VERSION "0.0.1"

NS_ :

BS_:

BU_: orin front_left_wheel back_left_wheel back_right_wheel front_right_wheel front_left_pivot back_left_pivot back_right_pivot front_right_pivot

BO_ 16 flw_all_stop: 0 orin

BO_ 17 flw_twitch_forward: 0 orin

BO_ 18 flw_twitch_backward: 0 orin

BO_ 19 flw_drive_at_speed: 2 orin
 SG_ velocity : 7|16@0- (1,0) [0|0] ""  front_left_wheel

BO_ 20 flw_drive_to_position: 2 orin
 SG_ position : 7|16@0- (1,0) [0|0] ""  front_left_wheel

BO_ 21 flw_drive_at_current: 2 orin
 SG_ effort : 7|16@0- (1,0) [0|0] ""  front_left_wheel

BO_ 22 flw_drive_open_loop: 4 orin
 SG_ open_loop_velocity : 23|16@0- (1,0) [0|0] ""  front_left_wheel
 SG_ open_loop_current : 7|16@0- (1,0) [0|0] ""  front_left_wheel

BO_ 23 flw_home_rotor: 0 orin

BO_ 24 flw_zero_resolver: 0 orin

BO_ 25 flw_get_configuration: 1 orin
 SG_ configuration : 7|8@0- (1,0) [0|0] ""  front_left_wheel

BO_ 26 flw_set_configuration: 4 orin
 SG_ shift_amount_0000_0001_0002_0004 m9 : 31|8@0+ (1,0) [0|0] "" Vector__XXX
 SG_ shift_amount_0000_0001_0002_0004 m8 : 31|8@0+ (1,0) [0|0] "" Vector__XXX
 SG_ shift_amount_0000_0001_0002_0004 m5 : 31|8@0+ (1,0) [0|0] "" Vector__XXX
 SG_ shift_amount_0000_0001_0002_0004 m4 : 31|8@0+ (1,0) [0|0] "" Vector__XXX
 SG_ shift_amount_0000_0001_0002_0004 m2 : 31|8@0+ (1,0) [0|0] "" Vector__XXX
 SG_ shift_amount_0000_0001_0002_0004 m1 : 31|8@0+ (1,0) [0|0] "" Vector__XXX
 SG_ speed_0000_0001_0002 m14 : 15|8@0+ (1,0) [0|0] "" Vector__XXX
 SG_ speed_0000_0001_0002 m13 : 15|8@0+ (1,0) [0|0] "" Vector__XXX
 SG_ speed_0000_0001_0002 m12 : 15|8@0+ (1,0) [0|0] "" Vector__XXX
 SG_ speed_0000_0001_0002 m11 : 15|8@0+ (1,0) [0|0] "" Vector__XXX
 SG_ max_position m10 : 15|16@0+ (1,0) [0|0] "" Vector__XXX
 SG_ fractional_0000_0001_0002_0_0004 m9 : 15|16@0+ (1,0) [0|0] "" Vector__XXX
 SG_ fractional_0000_0001_0002_0_0004 m8 : 15|16@0+ (1,0) [0|0] "" Vector__XXX
 SG_ min_interval m7 : 15|16@0+ (1,0) [0|0] "" Vector__XXX
 SG_ max_velocity m6 : 15|16@0+ (1,0) [0|0] "" Vector__XXX
 SG_ fractional_0000_0001_0002_0_0004 m5 : 15|16@0+ (1,0) [0|0] "" Vector__XXX
 SG_ fractional_0000_0001_0002_0_0004 m4 : 15|16@0+ (1,0) [0|0] "" Vector__XXX
 SG_ max_current m3 : 15|16@0+ (1,0) [0|0] "" Vector__XXX
 SG_ fractional_0000_0001_0002_0_0004 m2 : 15|16@0+ (1,0) [0|0] "" Vector__XXX
 SG_ fractional_0000_0001_0002_0_0004 m1 : 15|16@0+ (1,0) [0|0] "" Vector__XXX
 SG_ value m0 : 15|8@0+ (1,0) [0|0] "" Vector__XXX
 SG_ configuration M : 7|8@0+ (1,0) [0|0] ""  front_left_wheel

BO_ 27 flw_reset_blcmd: 0 orin

BO_ 28 flw_reset_resolver: 0 orin

BO_ 29 flw_read_gate_driver_fault: 0 orin

BO_ 1041 flw_telemetry_packet_1: 4 front_left_wheel
 SG_ q_current : 23|16@0- (1,0) [0|0] ""  orin
 SG_ velocity : 7|16@0- (1,0) [0|0] ""  orin

BO_ 1042 flw_telemetry_packet_2: 4 front_left_wheel
 SG_ d_current : 23|16@0- (1,0) [0|0] ""  orin
 SG_ interval : 7|16@0- (1,0) [0|0] ""  orin

BO_ 1043 flw_telemetry_packet_3: 4 front_left_wheel
 SG_ resolver_velocity : 23|16@0- (1,0) [0|0] ""  orin
 SG_ resolver_position : 7|16@0- (1,0) [0|0] ""  orin

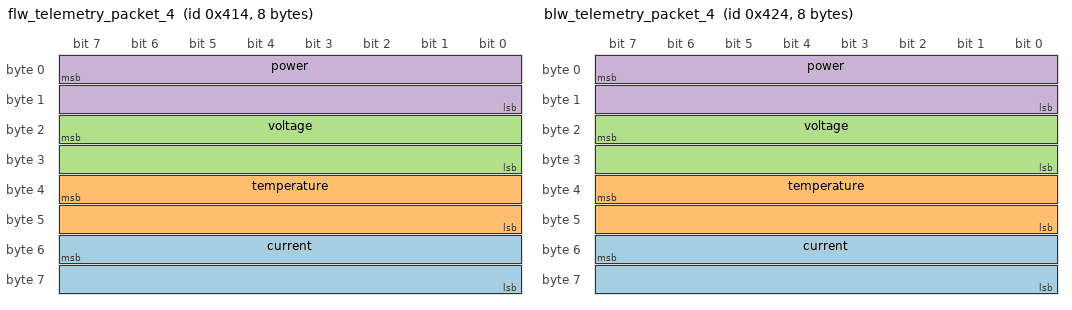
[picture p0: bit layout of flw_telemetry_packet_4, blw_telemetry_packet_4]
BO_ 1044 flw_telemetry_packet_4: 8 front_left_wheel
 SG_ current : 55|16@0- (1,0) [0|0] ""  orin
 SG_ temperature : 39|16@0- (1,0) [0|0] ""  orin
 SG_ voltage : 23|16@0- (1,0) [0|0] ""  orin
 SG_ power : 7|16@0- (1,0) [0|0] ""  orin

BO_ 1040 flw_log: 2 front_left_wheel
 SG_ gate_driver_condition m3 : 15|8@0+ (1,0) [0|0] "" Vector__XXX
 SG_ info_message m2 : 15|8@0- (1,0) [0|0] "" Vector__XXX
 SG_ warning_message m1 : 15|8@0- (1,0) [0|0] "" Vector__XXX
 SG_ error_message m0 : 15|8@0- (1,0) [0|0] "" Vector__XXX
 SG_ log_message M : 7|8@0- (1,0) [0|0] ""  orin

BO_ 1049 flw_current_configuration: 4 front_left_wheel
 SG_ shift_amount_0000_0001_0002_0004 m9 : 31|8@0+ (1,0) [0|0] "" Vector__XXX
 SG_ shift_amount_0000_0001_0002_0004 m8 : 31|8@0+ (1,0) [0|0] "" Vector__XXX
 SG_ shift_amount_0000_0001_0002_0004 m5 : 31|8@0+ (1,0) [0|0] "" Vector__XXX
 SG_ shift_amount_0000_0001_0002_0004 m4 : 31|8@0+ (1,0) [0|0] "" Vector__XXX
 SG_ shift_amount_0000_0001_0002_0004 m2 : 31|8@0+ (1,0) [0|0] "" Vector__XXX
 SG_ shift_amount_0000_0001_0002_0004 m1 : 31|8@0+ (1,0) [0|0] "" Vector__XXX
 SG_ speed_0000_0001_0002 m14 : 15|8@0+ (1,0) [0|0] "" Vector__XXX
 SG_ speed_0000_0001_0002 m13 : 15|8@0+ (1,0) [0|0] "" Vector__XXX
 SG_ speed_0000_0001_0002 m12 : 15|8@0+ (1,0) [0|0] "" Vector__XXX
 SG_ speed_0000_0001_0002 m11 : 15|8@0+ (1,0) [0|0] "" Vector__XXX
 SG_ max_position m10 : 15|16@0+ (1,0) [0|0] "" Vector__XXX
 SG_ fractional_0000_0001_0002_0_0004 m9 : 15|16@0+ (1,0) [0|0] "" Vector__XXX
 SG_ fractional_0000_0001_0002_0_0004 m8 : 15|16@0+ (1,0) [0|0] "" Vector__XXX
 SG_ min_interval m7 : 15|16@0+ (1,0) [0|0] "" Vector__XXX
 SG_ max_velocity m6 : 15|16@0+ (1,0) [0|0] "" Vector__XXX
 SG_ fractional_0000_0001_0002_0_0004 m5 : 15|16@0+ (1,0) [0|0] "" Vector__XXX
 SG_ fractional_0000_0001_0002_0_0004 m4 : 15|16@0+ (1,0) [0|0] "" Vector__XXX
 SG_ max_current m3 : 15|16@0+ (1,0) [0|0] "" Vector__XXX
 SG_ fractional_0000_0001_0002_0_0004 m2 : 15|16@0+ (1,0) [0|0] "" Vector__XXX
 SG_ fractional_0000_0001_0002_0_0004 m1 : 15|16@0+ (1,0) [0|0] "" Vector__XXX
 SG_ value m0 : 15|8@0+ (1,0) [0|0] "" Vector__XXX
 SG_ configuration M : 7|8@0+ (1,0) [0|0] ""  orin

BO_ 32 blw_all_stop: 0 orin

BO_ 33 blw_twitch_forward: 0 orin

BO_ 34 blw_twitch_backward: 0 orin

BO_ 35 blw_drive_at_speed: 2 orin
 SG_ velocity : 7|16@0- (1,0) [0|0] ""  back_left_wheel

BO_ 36 blw_drive_to_position: 2 orin
 SG_ position : 7|16@0- (1,0) [0|0] ""  back_left_wheel

BO_ 37 blw_drive_at_current: 2 orin
 SG_ effort : 7|16@0- (1,0) [0|0] ""  back_left_wheel

BO_ 38 blw_drive_open_loop: 4 orin
 SG_ open_loop_velocity : 23|16@0- (1,0) [0|0] ""  back_left_wheel
 SG_ open_loop_current : 7|16@0- (1,0) [0|0] ""  back_left_wheel

BO_ 39 blw_home_rotor: 0 orin

BO_ 40 blw_zero_resolver: 0 orin

BO_ 41 blw_get_configuration: 1 orin
 SG_ configuration : 7|8@0- (1,0) [0|0] ""  back_left_wheel

BO_ 42 blw_set_configuration: 4 orin
 SG_ shift_amount_0000_0001_0002_0004 m9 : 31|8@0+ (1,0) [0|0] "" Vector__XXX
 SG_ shift_amount_0000_0001_0002_0004 m8 : 31|8@0+ (1,0) [0|0] "" Vector__XXX
 SG_ shift_amount_0000_0001_0002_0004 m5 : 31|8@0+ (1,0) [0|0] "" Vector__XXX
 SG_ shift_amount_0000_0001_0002_0004 m4 : 31|8@0+ (1,0) [0|0] "" Vector__XXX
 SG_ shift_amount_0000_0001_0002_0004 m2 : 31|8@0+ (1,0) [0|0] "" Vector__XXX
 SG_ shift_amount_0000_0001_0002_0004 m1 : 31|8@0+ (1,0) [0|0] "" Vector__XXX
 SG_ speed_0000_0001_0002 m14 : 15|8@0+ (1,0) [0|0] "" Vector__XXX
 SG_ speed_0000_0001_0002 m13 : 15|8@0+ (1,0) [0|0] "" Vector__XXX
 SG_ speed_0000_0001_0002 m12 : 15|8@0+ (1,0) [0|0] "" Vector__XXX
 SG_ speed_0000_0001_0002 m11 : 15|8@0+ (1,0) [0|0] "" Vector__XXX
 SG_ max_position m10 : 15|16@0+ (1,0) [0|0] "" Vector__XXX
 SG_ fractional_0000_0001_0002_0_0004 m9 : 15|16@0+ (1,0) [0|0] "" Vector__XXX
 SG_ fractional_0000_0001_0002_0_0004 m8 : 15|16@0+ (1,0) [0|0] "" Vector__XXX
 SG_ min_interval m7 : 15|16@0+ (1,0) [0|0] "" Vector__XXX
 SG_ max_velocity m6 : 15|16@0+ (1,0) [0|0] "" Vector__XXX
 SG_ fractional_0000_0001_0002_0_0004 m5 : 15|16@0+ (1,0) [0|0] "" Vector__XXX
 SG_ fractional_0000_0001_0002_0_0004 m4 : 15|16@0+ (1,0) [0|0] "" Vector__XXX
 SG_ max_current m3 : 15|16@0+ (1,0) [0|0] "" Vector__XXX
 SG_ fractional_0000_0001_0002_0_0004 m2 : 15|16@0+ (1,0) [0|0] "" Vector__XXX
 SG_ fractional_0000_0001_0002_0_0004 m1 : 15|16@0+ (1,0) [0|0] "" Vector__XXX
 SG_ value m0 : 15|8@0+ (1,0) [0|0] "" Vector__XXX
 SG_ configuration M : 7|8@0+ (1,0) [0|0] ""  back_left_wheel

BO_ 43 blw_reset_blcmd: 0 orin

BO_ 44 blw_reset_resolver: 0 orin

BO_ 45 blw_read_gate_driver_fault: 0 orin

BO_ 1057 blw_telemetry_packet_1: 4 back_left_wheel
 SG_ q_current : 23|16@0- (1,0) [0|0] ""  orin
 SG_ velocity : 7|16@0- (1,0) [0|0] ""  orin

BO_ 1058 blw_telemetry_packet_2: 4 back_left_wheel
 SG_ d_current : 23|16@0- (1,0) [0|0] ""  orin
 SG_ interval : 7|16@0- (1,0) [0|0] ""  orin

BO_ 1059 blw_telemetry_packet_3: 4 back_left_wheel
 SG_ resolver_velocity : 23|16@0- (1,0) [0|0] ""  orin
 SG_ resolver_position : 7|16@0- (1,0) [0|0] ""  orin

BO_ 1060 blw_telemetry_packet_4: 8 back_left_wheel
 SG_ current : 55|16@0- (1,0) [0|0] ""  orin
 SG_ temperature : 39|16@0- (1,0) [0|0] ""  orin
 SG_ voltage : 23|16@0- (1,0) [0|0] ""  orin
 SG_ power : 7|16@0- (1,0) [0|0] ""  orin

BO_ 1056 blw_log: 2 back_left_wheel
 SG_ gate_driver_condition m3 : 15|8@0+ (1,0) [0|0] "" Vector__XXX
 SG_ info_message m2 : 15|8@0- (1,0) [0|0] "" Vector__XXX
 SG_ warning_message m1 : 15|8@0- (1,0) [0|0] "" Vector__XXX
 SG_ error_message m0 : 15|8@0- (1,0) [0|0] "" Vector__XXX
 SG_ log_message M : 7|8@0- (1,0) [0|0] ""  orin

BO_ 1065 blw_current_configuration: 4 back_left_wheel
 SG_ shift_amount_0000_0001_0002_0004 m9 : 31|8@0+ (1,0) [0|0] "" Vector__XXX
 SG_ shift_amount_0000_0001_0002_0004 m8 : 31|8@0+ (1,0) [0|0] "" Vector__XXX
 SG_ shift_amount_0000_0001_0002_0004 m5 : 31|8@0+ (1,0) [0|0] "" Vector__XXX
 SG_ shift_amount_0000_0001_0002_0004 m4 : 31|8@0+ (1,0) [0|0] "" Vector__XXX
 SG_ shift_amount_0000_0001_0002_0004 m2 : 31|8@0+ (1,0) [0|0] "" Vector__XXX
 SG_ shift_amount_0000_0001_0002_0004 m1 : 31|8@0+ (1,0) [0|0] "" Vector__XXX
 SG_ speed_0000_0001_0002 m14 : 15|8@0+ (1,0) [0|0] "" Vector__XXX
 SG_ speed_0000_0001_0002 m13 : 15|8@0+ (1,0) [0|0] "" Vector__XXX
 SG_ speed_0000_0001_0002 m12 : 15|8@0+ (1,0) [0|0] "" Vector__XXX
 SG_ speed_0000_0001_0002 m11 : 15|8@0+ (1,0) [0|0] "" Vector__XXX
 SG_ max_position m10 : 15|16@0+ (1,0) [0|0] "" Vector__XXX
 SG_ fractional_0000_0001_0002_0_0004 m9 : 15|16@0+ (1,0) [0|0] "" Vector__XXX
 SG_ fractional_0000_0001_0002_0_0004 m8 : 15|16@0+ (1,0) [0|0] "" Vector__XXX
 SG_ min_interval m7 : 15|16@0+ (1,0) [0|0] "" Vector__XXX
 SG_ max_velocity m6 : 15|16@0+ (1,0) [0|0] "" Vector__XXX
 SG_ fractional_0000_0001_0002_0_0004 m5 : 15|16@0+ (1,0) [0|0] "" Vector__XXX
 SG_ fractional_0000_0001_0002_0_0004 m4 : 15|16@0+ (1,0) [0|0] "" Vector__XXX
 SG_ max_current m3 : 15|16@0+ (1,0) [0|0] "" Vector__XXX
 SG_ fractional_0000_0001_0002_0_0004 m2 : 15|16@0+ (1,0) [0|0] "" Vector__XXX
 SG_ fractional_0000_0001_0002_0_0004 m1 : 15|16@0+ (1,0) [0|0] "" Vector__XXX
 SG_ value m0 : 15|8@0+ (1,0) [0|0] "" Vector__XXX
 SG_ configuration M : 7|8@0+ (1,0) [0|0] ""  orin

BO_ 48 brw_all_stop: 0 orin

BO_ 49 brw_twitch_forward: 0 orin

BO_ 50 brw_twitch_backward: 0 orin

BO_ 51 brw_drive_at_speed: 2 orin
 SG_ velocity : 7|16@0- (1,0) [0|0] ""  back_right_wheel

BO_ 52 brw_drive_to_position: 2 orin
 SG_ position : 7|16@0- (1,0) [0|0] ""  back_right_wheel

BO_ 53 brw_drive_at_current: 2 orin
 SG_ effort : 7|16@0- (1,0) [0|0] ""  back_right_wheel

BO_ 54 brw_drive_open_loop: 4 orin
 SG_ open_loop_velocity : 23|16@0- (1,0) [0|0] ""  back_right_wheel
 SG_ open_loop_current : 7|16@0- (1,0) [0|0] ""  back_right_wheel

BO_ 55 brw_home_rotor: 0 orin

BO_ 56 brw_zero_resolver: 0 orin

BO_ 57 brw_get_configuration: 1 orin
 SG_ configuration : 7|8@0- (1,0) [0|0] ""  back_right_wheel

BO_ 58 brw_set_configuration: 4 orin
 SG_ shift_amount_0000_0001_0002_0004 m9 : 31|8@0+ (1,0) [0|0] "" Vector__XXX
 SG_ shift_amount_0000_0001_0002_0004 m8 : 31|8@0+ (1,0) [0|0] "" Vector__XXX
 SG_ shift_amount_0000_0001_0002_0004 m5 : 31|8@0+ (1,0) [0|0] "" Vector__XXX
 SG_ shift_amount_0000_0001_0002_0004 m4 : 31|8@0+ (1,0) [0|0] "" Vector__XXX
 SG_ shift_amount_0000_0001_0002_0004 m2 : 31|8@0+ (1,0) [0|0] "" Vector__XXX
 SG_ shift_amount_0000_0001_0002_0004 m1 : 31|8@0+ (1,0) [0|0] "" Vector__XXX
 SG_ speed_0000_0001_0002 m14 : 15|8@0+ (1,0) [0|0] "" Vector__XXX
 SG_ speed_0000_0001_0002 m13 : 15|8@0+ (1,0) [0|0] "" Vector__XXX
 SG_ speed_0000_0001_0002 m12 : 15|8@0+ (1,0) [0|0] "" Vector__XXX
 SG_ speed_0000_0001_0002 m11 : 15|8@0+ (1,0) [0|0] "" Vector__XXX
 SG_ max_position m10 : 15|16@0+ (1,0) [0|0] "" Vector__XXX
 SG_ fractional_0000_0001_0002_0_0004 m9 : 15|16@0+ (1,0) [0|0] "" Vector__XXX
 SG_ fractional_0000_0001_0002_0_0004 m8 : 15|16@0+ (1,0) [0|0] "" Vector__XXX
 SG_ min_interval m7 : 15|16@0+ (1,0) [0|0] "" Vector__XXX
 SG_ max_velocity m6 : 15|16@0+ (1,0) [0|0] "" Vector__XXX
 SG_ fractional_0000_0001_0002_0_0004 m5 : 15|16@0+ (1,0) [0|0] "" Vector__XXX
 SG_ fractional_0000_0001_0002_0_0004 m4 : 15|16@0+ (1,0) [0|0] "" Vector__XXX
 SG_ max_current m3 : 15|16@0+ (1,0) [0|0] "" Vector__XXX
 SG_ fractional_0000_0001_0002_0_0004 m2 : 15|16@0+ (1,0) [0|0] "" Vector__XXX
 SG_ fractional_0000_0001_0002_0_0004 m1 : 15|16@0+ (1,0) [0|0] "" Vector__XXX
 SG_ value m0 : 15|8@0+ (1,0) [0|0] "" Vector__XXX
 SG_ configuration M : 7|8@0+ (1,0) [0|0] ""  back_right_wheel

BO_ 59 brw_reset_blcmd: 0 orin

BO_ 60 brw_reset_resolver: 0 orin

BO_ 61 brw_read_gate_driver_fault: 0 orin

BO_ 1073 brw_telemetry_packet_1: 4 back_right_wheel
 SG_ q_current : 23|16@0- (1,0) [0|0] ""  orin
 SG_ velocity : 7|16@0- (1,0) [0|0] ""  orin

BO_ 1074 brw_telemetry_packet_2: 4 back_right_wheel
 SG_ d_current : 23|16@0- (1,0) [0|0] ""  orin
 SG_ interval : 7|16@0- (1,0) [0|0] ""  orin

BO_ 1075 brw_telemetry_packet_3: 4 back_right_wheel
 SG_ resolver_velocity : 23|16@0- (1,0) [0|0] ""  orin
 SG_ resolver_position : 7|16@0- (1,0) [0|0] ""  orin

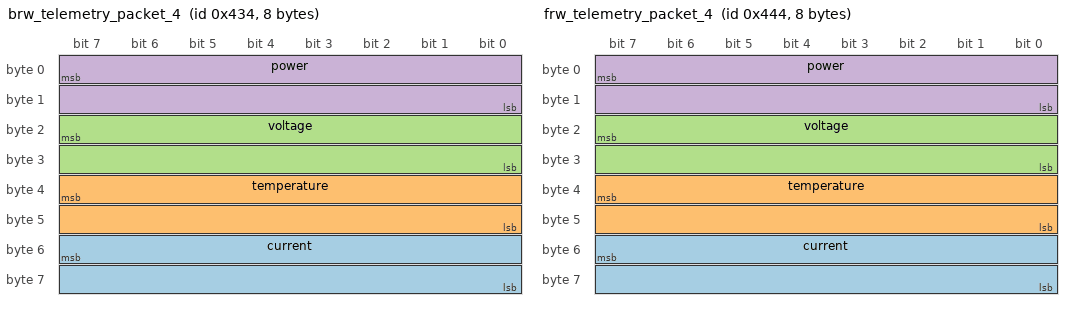
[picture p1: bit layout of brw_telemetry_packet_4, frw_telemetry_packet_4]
BO_ 1076 brw_telemetry_packet_4: 8 back_right_wheel
 SG_ current : 55|16@0- (1,0) [0|0] ""  orin
 SG_ temperature : 39|16@0- (1,0) [0|0] ""  orin
 SG_ voltage : 23|16@0- (1,0) [0|0] ""  orin
 SG_ power : 7|16@0- (1,0) [0|0] ""  orin

BO_ 1072 brw_log: 2 back_right_wheel
 SG_ gate_driver_condition m3 : 15|8@0+ (1,0) [0|0] "" Vector__XXX
 SG_ info_message m2 : 15|8@0- (1,0) [0|0] "" Vector__XXX
 SG_ warning_message m1 : 15|8@0- (1,0) [0|0] "" Vector__XXX
 SG_ error_message m0 : 15|8@0- (1,0) [0|0] "" Vector__XXX
 SG_ log_message M : 7|8@0- (1,0) [0|0] ""  orin

BO_ 1081 brw_current_configuration: 4 back_right_wheel
 SG_ shift_amount_0000_0001_0002_0004 m9 : 31|8@0+ (1,0) [0|0] "" Vector__XXX
 SG_ shift_amount_0000_0001_0002_0004 m8 : 31|8@0+ (1,0) [0|0] "" Vector__XXX
 SG_ shift_amount_0000_0001_0002_0004 m5 : 31|8@0+ (1,0) [0|0] "" Vector__XXX
 SG_ shift_amount_0000_0001_0002_0004 m4 : 31|8@0+ (1,0) [0|0] "" Vector__XXX
 SG_ shift_amount_0000_0001_0002_0004 m2 : 31|8@0+ (1,0) [0|0] "" Vector__XXX
 SG_ shift_amount_0000_0001_0002_0004 m1 : 31|8@0+ (1,0) [0|0] "" Vector__XXX
 SG_ speed_0000_0001_0002 m14 : 15|8@0+ (1,0) [0|0] "" Vector__XXX
 SG_ speed_0000_0001_0002 m13 : 15|8@0+ (1,0) [0|0] "" Vector__XXX
 SG_ speed_0000_0001_0002 m12 : 15|8@0+ (1,0) [0|0] "" Vector__XXX
 SG_ speed_0000_0001_0002 m11 : 15|8@0+ (1,0) [0|0] "" Vector__XXX
 SG_ max_position m10 : 15|16@0+ (1,0) [0|0] "" Vector__XXX
 SG_ fractional_0000_0001_0002_0_0004 m9 : 15|16@0+ (1,0) [0|0] "" Vector__XXX
 SG_ fractional_0000_0001_0002_0_0004 m8 : 15|16@0+ (1,0) [0|0] "" Vector__XXX
 SG_ min_interval m7 : 15|16@0+ (1,0) [0|0] "" Vector__XXX
 SG_ max_velocity m6 : 15|16@0+ (1,0) [0|0] "" Vector__XXX
 SG_ fractional_0000_0001_0002_0_0004 m5 : 15|16@0+ (1,0) [0|0] "" Vector__XXX
 SG_ fractional_0000_0001_0002_0_0004 m4 : 15|16@0+ (1,0) [0|0] "" Vector__XXX
 SG_ max_current m3 : 15|16@0+ (1,0) [0|0] "" Vector__XXX
 SG_ fractional_0000_0001_0002_0_0004 m2 : 15|16@0+ (1,0) [0|0] "" Vector__XXX
 SG_ fractional_0000_0001_0002_0_0004 m1 : 15|16@0+ (1,0) [0|0] "" Vector__XXX
 SG_ value m0 : 15|8@0+ (1,0) [0|0] "" Vector__XXX
 SG_ configuration M : 7|8@0+ (1,0) [0|0] ""  orin

BO_ 64 frw_all_stop: 0 orin

BO_ 65 frw_twitch_forward: 0 orin

BO_ 66 frw_twitch_backward: 0 orin

BO_ 67 frw_drive_at_speed: 2 orin
 SG_ velocity : 7|16@0- (1,0) [0|0] ""  front_right_wheel

BO_ 68 frw_drive_to_position: 2 orin
 SG_ position : 7|16@0- (1,0) [0|0] ""  front_right_wheel

BO_ 69 frw_drive_at_current: 2 orin
 SG_ effort : 7|16@0- (1,0) [0|0] ""  front_right_wheel

BO_ 70 frw_drive_open_loop: 4 orin
 SG_ open_loop_velocity : 23|16@0- (1,0) [0|0] ""  front_right_wheel
 SG_ open_loop_current : 7|16@0- (1,0) [0|0] ""  front_right_wheel

BO_ 71 frw_home_rotor: 0 orin

BO_ 72 frw_zero_resolver: 0 orin

BO_ 73 frw_get_configuration: 1 orin
 SG_ configuration : 7|8@0- (1,0) [0|0] ""  front_right_wheel

BO_ 74 frw_set_configuration: 4 orin
 SG_ shift_amount_0000_0001_0002_0004 m9 : 31|8@0+ (1,0) [0|0] "" Vector__XXX
 SG_ shift_amount_0000_0001_0002_0004 m8 : 31|8@0+ (1,0) [0|0] "" Vector__XXX
 SG_ shift_amount_0000_0001_0002_0004 m5 : 31|8@0+ (1,0) [0|0] "" Vector__XXX
 SG_ shift_amount_0000_0001_0002_0004 m4 : 31|8@0+ (1,0) [0|0] "" Vector__XXX
 SG_ shift_amount_0000_0001_0002_0004 m2 : 31|8@0+ (1,0) [0|0] "" Vector__XXX
 SG_ shift_amount_0000_0001_0002_0004 m1 : 31|8@0+ (1,0) [0|0] "" Vector__XXX
 SG_ speed_0000_0001_0002 m14 : 15|8@0+ (1,0) [0|0] "" Vector__XXX
 SG_ speed_0000_0001_0002 m13 : 15|8@0+ (1,0) [0|0] "" Vector__XXX
 SG_ speed_0000_0001_0002 m12 : 15|8@0+ (1,0) [0|0] "" Vector__XXX
 SG_ speed_0000_0001_0002 m11 : 15|8@0+ (1,0) [0|0] "" Vector__XXX
 SG_ max_position m10 : 15|16@0+ (1,0) [0|0] "" Vector__XXX
 SG_ fractional_0000_0001_0002_0_0004 m9 : 15|16@0+ (1,0) [0|0] "" Vector__XXX
 SG_ fractional_0000_0001_0002_0_0004 m8 : 15|16@0+ (1,0) [0|0] "" Vector__XXX
 SG_ min_interval m7 : 15|16@0+ (1,0) [0|0] "" Vector__XXX
 SG_ max_velocity m6 : 15|16@0+ (1,0) [0|0] "" Vector__XXX
 SG_ fractional_0000_0001_0002_0_0004 m5 : 15|16@0+ (1,0) [0|0] "" Vector__XXX
 SG_ fractional_0000_0001_0002_0_0004 m4 : 15|16@0+ (1,0) [0|0] "" Vector__XXX
 SG_ max_current m3 : 15|16@0+ (1,0) [0|0] "" Vector__XXX
 SG_ fractional_0000_0001_0002_0_0004 m2 : 15|16@0+ (1,0) [0|0] "" Vector__XXX
 SG_ fractional_0000_0001_0002_0_0004 m1 : 15|16@0+ (1,0) [0|0] "" Vector__XXX
 SG_ value m0 : 15|8@0+ (1,0) [0|0] "" Vector__XXX
 SG_ configuration M : 7|8@0+ (1,0) [0|0] ""  front_right_wheel

BO_ 75 frw_reset_blcmd: 0 orin

BO_ 76 frw_reset_resolver: 0 orin

BO_ 77 frw_read_gate_driver_fault: 0 orin

BO_ 1089 frw_telemetry_packet_1: 4 front_right_wheel
 SG_ q_current : 23|16@0- (1,0) [0|0] ""  orin
 SG_ velocity : 7|16@0- (1,0) [0|0] ""  orin

BO_ 1090 frw_telemetry_packet_2: 4 front_right_wheel
 SG_ d_current : 23|16@0- (1,0) [0|0] ""  orin
 SG_ interval : 7|16@0- (1,0) [0|0] ""  orin

BO_ 1091 frw_telemetry_packet_3: 4 front_right_wheel
 SG_ resolver_velocity : 23|16@0- (1,0) [0|0] ""  orin
 SG_ resolver_position : 7|16@0- (1,0) [0|0] ""  orin

BO_ 1092 frw_telemetry_packet_4: 8 front_right_wheel
 SG_ current : 55|16@0- (1,0) [0|0] ""  orin
 SG_ temperature : 39|16@0- (1,0) [0|0] ""  orin
 SG_ voltage : 23|16@0- (1,0) [0|0] ""  orin
 SG_ power : 7|16@0- (1,0) [0|0] ""  orin

BO_ 1088 frw_log: 2 front_right_wheel
 SG_ gate_driver_condition m3 : 15|8@0+ (1,0) [0|0] "" Vector__XXX
 SG_ info_message m2 : 15|8@0- (1,0) [0|0] "" Vector__XXX
 SG_ warning_message m1 : 15|8@0- (1,0) [0|0] "" Vector__XXX
 SG_ error_message m0 : 15|8@0- (1,0) [0|0] "" Vector__XXX
 SG_ log_message M : 7|8@0- (1,0) [0|0] ""  orin

BO_ 1097 frw_current_configuration: 4 front_right_wheel
 SG_ shift_amount_0000_0001_0002_0004 m9 : 31|8@0+ (1,0) [0|0] "" Vector__XXX
 SG_ shift_amount_0000_0001_0002_0004 m8 : 31|8@0+ (1,0) [0|0] "" Vector__XXX
 SG_ shift_amount_0000_0001_0002_0004 m5 : 31|8@0+ (1,0) [0|0] "" Vector__XXX
 SG_ shift_amount_0000_0001_0002_0004 m4 : 31|8@0+ (1,0) [0|0] "" Vector__XXX
 SG_ shift_amount_0000_0001_0002_0004 m2 : 31|8@0+ (1,0) [0|0] "" Vector__XXX
 SG_ shift_amount_0000_0001_0002_0004 m1 : 31|8@0+ (1,0) [0|0] "" Vector__XXX
 SG_ speed_0000_0001_0002 m14 : 15|8@0+ (1,0) [0|0] "" Vector__XXX
 SG_ speed_0000_0001_0002 m13 : 15|8@0+ (1,0) [0|0] "" Vector__XXX
 SG_ speed_0000_0001_0002 m12 : 15|8@0+ (1,0) [0|0] "" Vector__XXX
 SG_ speed_0000_0001_0002 m11 : 15|8@0+ (1,0) [0|0] "" Vector__XXX
 SG_ max_position m10 : 15|16@0+ (1,0) [0|0] "" Vector__XXX
 SG_ fractional_0000_0001_0002_0_0004 m9 : 15|16@0+ (1,0) [0|0] "" Vector__XXX
 SG_ fractional_0000_0001_0002_0_0004 m8 : 15|16@0+ (1,0) [0|0] "" Vector__XXX
 SG_ min_interval m7 : 15|16@0+ (1,0) [0|0] "" Vector__XXX
 SG_ max_velocity m6 : 15|16@0+ (1,0) [0|0] "" Vector__XXX
 SG_ fractional_0000_0001_0002_0_0004 m5 : 15|16@0+ (1,0) [0|0] "" Vector__XXX
 SG_ fractional_0000_0001_0002_0_0004 m4 : 15|16@0+ (1,0) [0|0] "" Vector__XXX
 SG_ max_current m3 : 15|16@0+ (1,0) [0|0] "" Vector__XXX
 SG_ fractional_0000_0001_0002_0_0004 m2 : 15|16@0+ (1,0) [0|0] "" Vector__XXX
 SG_ fractional_0000_0001_0002_0_0004 m1 : 15|16@0+ (1,0) [0|0] "" Vector__XXX
 SG_ value m0 : 15|8@0+ (1,0) [0|0] "" Vector__XXX
 SG_ configuration M : 7|8@0+ (1,0) [0|0] ""  orin

BO_ 80 flp_all_stop: 0 orin

BO_ 81 flp_twitch_forward: 0 orin

BO_ 82 flp_twitch_backward: 0 orin

BO_ 83 flp_drive_at_speed: 2 orin
 SG_ velocity : 7|16@0- (1,0) [0|0] ""  front_left_pivot

BO_ 84 flp_drive_to_position: 2 orin
 SG_ position : 7|16@0- (1,0) [0|0] ""  front_left_pivot

BO_ 85 flp_drive_at_current: 2 orin
 SG_ effort : 7|16@0- (1,0) [0|0] ""  front_left_pivot

BO_ 86 flp_drive_open_loop: 4 orin
 SG_ open_loop_velocity : 23|16@0- (1,0) [0|0] ""  front_left_pivot
 SG_ open_loop_current : 7|16@0- (1,0) [0|0] ""  front_left_pivot

BO_ 87 flp_home_rotor: 0 orin

BO_ 88 flp_zero_resolver: 0 orin

BO_ 89 flp_get_configuration: 1 orin
 SG_ configuration : 7|8@0- (1,0) [0|0] ""  front_left_pivot

BO_ 90 flp_set_configuration: 4 orin
 SG_ shift_amount_0000_0001_0002_0004 m9 : 31|8@0+ (1,0) [0|0] "" Vector__XXX
 SG_ shift_amount_0000_0001_0002_0004 m8 : 31|8@0+ (1,0) [0|0] "" Vector__XXX
 SG_ shift_amount_0000_0001_0002_0004 m5 : 31|8@0+ (1,0) [0|0] "" Vector__XXX
 SG_ shift_amount_0000_0001_0002_0004 m4 : 31|8@0+ (1,0) [0|0] "" Vector__XXX
 SG_ shift_amount_0000_0001_0002_0004 m2 : 31|8@0+ (1,0) [0|0] "" Vector__XXX
 SG_ shift_amount_0000_0001_0002_0004 m1 : 31|8@0+ (1,0) [0|0] "" Vector__XXX
 SG_ speed_0000_0001_0002 m14 : 15|8@0+ (1,0) [0|0] "" Vector__XXX
 SG_ speed_0000_0001_0002 m13 : 15|8@0+ (1,0) [0|0] "" Vector__XXX
 SG_ speed_0000_0001_0002 m12 : 15|8@0+ (1,0) [0|0] "" Vector__XXX
 SG_ speed_0000_0001_0002 m11 : 15|8@0+ (1,0) [0|0] "" Vector__XXX
 SG_ max_position m10 : 15|16@0+ (1,0) [0|0] "" Vector__XXX
 SG_ fractional_0000_0001_0002_0_0004 m9 : 15|16@0+ (1,0) [0|0] "" Vector__XXX
 SG_ fractional_0000_0001_0002_0_0004 m8 : 15|16@0+ (1,0) [0|0] "" Vector__XXX
 SG_ min_interval m7 : 15|16@0+ (1,0) [0|0] "" Vector__XXX
 SG_ max_velocity m6 : 15|16@0+ (1,0) [0|0] "" Vector__XXX
 SG_ fractional_0000_0001_0002_0_0004 m5 : 15|16@0+ (1,0) [0|0] "" Vector__XXX
 SG_ fractional_0000_0001_0002_0_0004 m4 : 15|16@0+ (1,0) [0|0] "" Vector__XXX
 SG_ max_current m3 : 15|16@0+ (1,0) [0|0] "" Vector__XXX
 SG_ fractional_0000_0001_0002_0_0004 m2 : 15|16@0+ (1,0) [0|0] "" Vector__XXX
 SG_ fractional_0000_0001_0002_0_0004 m1 : 15|16@0+ (1,0) [0|0] "" Vector__XXX
 SG_ value m0 : 15|8@0+ (1,0) [0|0] "" Vector__XXX
 SG_ configuration M : 7|8@0+ (1,0) [0|0] ""  front_left_pivot

BO_ 91 flp_reset_blcmd: 0 orin

BO_ 92 flp_reset_resolver: 0 orin

BO_ 93 flp_read_gate_driver_fault: 0 orin

BO_ 1105 flp_telemetry_packet_1: 4 front_left_pivot
 SG_ q_current : 23|16@0- (1,0) [0|0] ""  orin
 SG_ velocity : 7|16@0- (1,0) [0|0] ""  orin

BO_ 1106 flp_telemetry_packet_2: 4 front_left_pivot
 SG_ d_current : 23|16@0- (1,0) [0|0] ""  orin
 SG_ interval : 7|16@0- (1,0) [0|0] ""  orin

BO_ 1107 flp_telemetry_packet_3: 4 front_left_pivot
 SG_ resolver_velocity : 23|16@0- (1,0) [0|0] ""  orin
 SG_ resolver_position : 7|16@0- (1,0) [0|0] ""  orin

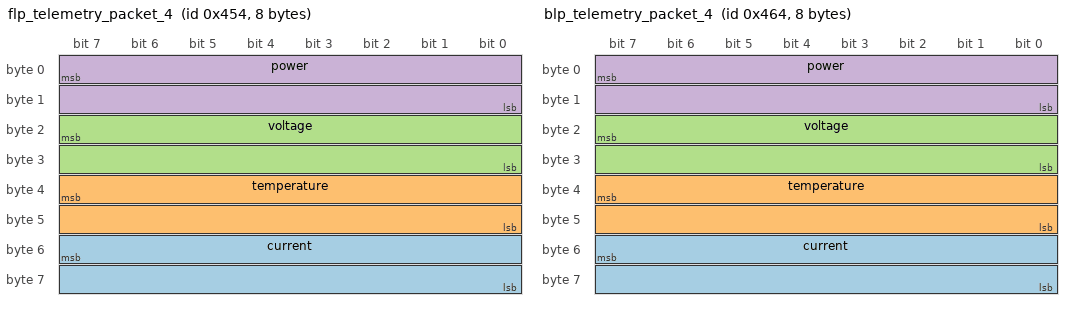
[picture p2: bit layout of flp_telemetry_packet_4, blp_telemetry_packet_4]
BO_ 1108 flp_telemetry_packet_4: 8 front_left_pivot
 SG_ current : 55|16@0- (1,0) [0|0] ""  orin
 SG_ temperature : 39|16@0- (1,0) [0|0] ""  orin
 SG_ voltage : 23|16@0- (1,0) [0|0] ""  orin
 SG_ power : 7|16@0- (1,0) [0|0] ""  orin

BO_ 1104 flp_log: 2 front_left_pivot
 SG_ gate_driver_condition m3 : 15|8@0+ (1,0) [0|0] "" Vector__XXX
 SG_ info_message m2 : 15|8@0- (1,0) [0|0] "" Vector__XXX
 SG_ warning_message m1 : 15|8@0- (1,0) [0|0] "" Vector__XXX
 SG_ error_message m0 : 15|8@0- (1,0) [0|0] "" Vector__XXX
 SG_ log_message M : 7|8@0- (1,0) [0|0] ""  orin

BO_ 1113 flp_current_configuration: 4 front_left_pivot
 SG_ shift_amount_0000_0001_0002_0004 m9 : 31|8@0+ (1,0) [0|0] "" Vector__XXX
 SG_ shift_amount_0000_0001_0002_0004 m8 : 31|8@0+ (1,0) [0|0] "" Vector__XXX
 SG_ shift_amount_0000_0001_0002_0004 m5 : 31|8@0+ (1,0) [0|0] "" Vector__XXX
 SG_ shift_amount_0000_0001_0002_0004 m4 : 31|8@0+ (1,0) [0|0] "" Vector__XXX
 SG_ shift_amount_0000_0001_0002_0004 m2 : 31|8@0+ (1,0) [0|0] "" Vector__XXX
 SG_ shift_amount_0000_0001_0002_0004 m1 : 31|8@0+ (1,0) [0|0] "" Vector__XXX
 SG_ speed_0000_0001_0002 m14 : 15|8@0+ (1,0) [0|0] "" Vector__XXX
 SG_ speed_0000_0001_0002 m13 : 15|8@0+ (1,0) [0|0] "" Vector__XXX
 SG_ speed_0000_0001_0002 m12 : 15|8@0+ (1,0) [0|0] "" Vector__XXX
 SG_ speed_0000_0001_0002 m11 : 15|8@0+ (1,0) [0|0] "" Vector__XXX
 SG_ max_position m10 : 15|16@0+ (1,0) [0|0] "" Vector__XXX
 SG_ fractional_0000_0001_0002_0_0004 m9 : 15|16@0+ (1,0) [0|0] "" Vector__XXX
 SG_ fractional_0000_0001_0002_0_0004 m8 : 15|16@0+ (1,0) [0|0] "" Vector__XXX
 SG_ min_interval m7 : 15|16@0+ (1,0) [0|0] "" Vector__XXX
 SG_ max_velocity m6 : 15|16@0+ (1,0) [0|0] "" Vector__XXX
 SG_ fractional_0000_0001_0002_0_0004 m5 : 15|16@0+ (1,0) [0|0] "" Vector__XXX
 SG_ fractional_0000_0001_0002_0_0004 m4 : 15|16@0+ (1,0) [0|0] "" Vector__XXX
 SG_ max_current m3 : 15|16@0+ (1,0) [0|0] "" Vector__XXX
 SG_ fractional_0000_0001_0002_0_0004 m2 : 15|16@0+ (1,0) [0|0] "" Vector__XXX
 SG_ fractional_0000_0001_0002_0_0004 m1 : 15|16@0+ (1,0) [0|0] "" Vector__XXX
 SG_ value m0 : 15|8@0+ (1,0) [0|0] "" Vector__XXX
 SG_ configuration M : 7|8@0+ (1,0) [0|0] ""  orin

BO_ 96 blp_all_stop: 0 orin

BO_ 97 blp_twitch_forward: 0 orin

BO_ 98 blp_twitch_backward: 0 orin

BO_ 99 blp_drive_at_speed: 2 orin
 SG_ velocity : 7|16@0- (1,0) [0|0] ""  back_left_pivot

BO_ 100 blp_drive_to_position: 2 orin
 SG_ position : 7|16@0- (1,0) [0|0] ""  back_left_pivot

BO_ 101 blp_drive_at_current: 2 orin
 SG_ effort : 7|16@0- (1,0) [0|0] ""  back_left_pivot

BO_ 102 blp_drive_open_loop: 4 orin
 SG_ open_loop_velocity : 23|16@0- (1,0) [0|0] ""  back_left_pivot
 SG_ open_loop_current : 7|16@0- (1,0) [0|0] ""  back_left_pivot

BO_ 103 blp_home_rotor: 0 orin

BO_ 104 blp_zero_resolver: 0 orin

BO_ 105 blp_get_configuration: 1 orin
 SG_ configuration : 7|8@0- (1,0) [0|0] ""  back_left_pivot

BO_ 106 blp_set_configuration: 4 orin
 SG_ shift_amount_0000_0001_0002_0004 m9 : 31|8@0+ (1,0) [0|0] "" Vector__XXX
 SG_ shift_amount_0000_0001_0002_0004 m8 : 31|8@0+ (1,0) [0|0] "" Vector__XXX
 SG_ shift_amount_0000_0001_0002_0004 m5 : 31|8@0+ (1,0) [0|0] "" Vector__XXX
 SG_ shift_amount_0000_0001_0002_0004 m4 : 31|8@0+ (1,0) [0|0] "" Vector__XXX
 SG_ shift_amount_0000_0001_0002_0004 m2 : 31|8@0+ (1,0) [0|0] "" Vector__XXX
 SG_ shift_amount_0000_0001_0002_0004 m1 : 31|8@0+ (1,0) [0|0] "" Vector__XXX
 SG_ speed_0000_0001_0002 m14 : 15|8@0+ (1,0) [0|0] "" Vector__XXX
 SG_ speed_0000_0001_0002 m13 : 15|8@0+ (1,0) [0|0] "" Vector__XXX
 SG_ speed_0000_0001_0002 m12 : 15|8@0+ (1,0) [0|0] "" Vector__XXX
 SG_ speed_0000_0001_0002 m11 : 15|8@0+ (1,0) [0|0] "" Vector__XXX
 SG_ max_position m10 : 15|16@0+ (1,0) [0|0] "" Vector__XXX
 SG_ fractional_0000_0001_0002_0_0004 m9 : 15|16@0+ (1,0) [0|0] "" Vector__XXX
 SG_ fractional_0000_0001_0002_0_0004 m8 : 15|16@0+ (1,0) [0|0] "" Vector__XXX
 SG_ min_interval m7 : 15|16@0+ (1,0) [0|0] "" Vector__XXX
 SG_ max_velocity m6 : 15|16@0+ (1,0) [0|0] "" Vector__XXX
 SG_ fractional_0000_0001_0002_0_0004 m5 : 15|16@0+ (1,0) [0|0] "" Vector__XXX
 SG_ fractional_0000_0001_0002_0_0004 m4 : 15|16@0+ (1,0) [0|0] "" Vector__XXX
 SG_ max_current m3 : 15|16@0+ (1,0) [0|0] "" Vector__XXX
 SG_ fractional_0000_0001_0002_0_0004 m2 : 15|16@0+ (1,0) [0|0] "" Vector__XXX
 SG_ fractional_0000_0001_0002_0_0004 m1 : 15|16@0+ (1,0) [0|0] "" Vector__XXX
 SG_ value m0 : 15|8@0+ (1,0) [0|0] "" Vector__XXX
 SG_ configuration M : 7|8@0+ (1,0) [0|0] ""  back_left_pivot

BO_ 107 blp_reset_blcmd: 0 orin

BO_ 108 blp_reset_resolver: 0 orin

BO_ 109 blp_read_gate_driver_fault: 0 orin

BO_ 1121 blp_telemetry_packet_1: 4 back_left_pivot
 SG_ q_current : 23|16@0- (1,0) [0|0] ""  orin
 SG_ velocity : 7|16@0- (1,0) [0|0] ""  orin

BO_ 1122 blp_telemetry_packet_2: 4 back_left_pivot
 SG_ d_current : 23|16@0- (1,0) [0|0] ""  orin
 SG_ interval : 7|16@0- (1,0) [0|0] ""  orin

BO_ 1123 blp_telemetry_packet_3: 4 back_left_pivot
 SG_ resolver_velocity : 23|16@0- (1,0) [0|0] ""  orin
 SG_ resolver_position : 7|16@0- (1,0) [0|0] ""  orin

BO_ 1124 blp_telemetry_packet_4: 8 back_left_pivot
 SG_ current : 55|16@0- (1,0) [0|0] ""  orin
 SG_ temperature : 39|16@0- (1,0) [0|0] ""  orin
 SG_ voltage : 23|16@0- (1,0) [0|0] ""  orin
 SG_ power : 7|16@0- (1,0) [0|0] ""  orin

BO_ 1120 blp_log: 2 back_left_pivot
 SG_ gate_driver_condition m3 : 15|8@0+ (1,0) [0|0] "" Vector__XXX
 SG_ info_message m2 : 15|8@0- (1,0) [0|0] "" Vector__XXX
 SG_ warning_message m1 : 15|8@0- (1,0) [0|0] "" Vector__XXX
 SG_ error_message m0 : 15|8@0- (1,0) [0|0] "" Vector__XXX
 SG_ log_message M : 7|8@0- (1,0) [0|0] ""  orin

BO_ 1129 blp_current_configuration: 4 back_left_pivot
 SG_ shift_amount_0000_0001_0002_0004 m9 : 31|8@0+ (1,0) [0|0] "" Vector__XXX
 SG_ shift_amount_0000_0001_0002_0004 m8 : 31|8@0+ (1,0) [0|0] "" Vector__XXX
 SG_ shift_amount_0000_0001_0002_0004 m5 : 31|8@0+ (1,0) [0|0] "" Vector__XXX
 SG_ shift_amount_0000_0001_0002_0004 m4 : 31|8@0+ (1,0) [0|0] "" Vector__XXX
 SG_ shift_amount_0000_0001_0002_0004 m2 : 31|8@0+ (1,0) [0|0] "" Vector__XXX
 SG_ shift_amount_0000_0001_0002_0004 m1 : 31|8@0+ (1,0) [0|0] "" Vector__XXX
 SG_ speed_0000_0001_0002 m14 : 15|8@0+ (1,0) [0|0] "" Vector__XXX
 SG_ speed_0000_0001_0002 m13 : 15|8@0+ (1,0) [0|0] "" Vector__XXX
 SG_ speed_0000_0001_0002 m12 : 15|8@0+ (1,0) [0|0] "" Vector__XXX
 SG_ speed_0000_0001_0002 m11 : 15|8@0+ (1,0) [0|0] "" Vector__XXX
 SG_ max_position m10 : 15|16@0+ (1,0) [0|0] "" Vector__XXX
 SG_ fractional_0000_0001_0002_0_0004 m9 : 15|16@0+ (1,0) [0|0] "" Vector__XXX
 SG_ fractional_0000_0001_0002_0_0004 m8 : 15|16@0+ (1,0) [0|0] "" Vector__XXX
 SG_ min_interval m7 : 15|16@0+ (1,0) [0|0] "" Vector__XXX
 SG_ max_velocity m6 : 15|16@0+ (1,0) [0|0] "" Vector__XXX
 SG_ fractional_0000_0001_0002_0_0004 m5 : 15|16@0+ (1,0) [0|0] "" Vector__XXX
 SG_ fractional_0000_0001_0002_0_0004 m4 : 15|16@0+ (1,0) [0|0] "" Vector__XXX
 SG_ max_current m3 : 15|16@0+ (1,0) [0|0] "" Vector__XXX
 SG_ fractional_0000_0001_0002_0_0004 m2 : 15|16@0+ (1,0) [0|0] "" Vector__XXX
 SG_ fractional_0000_0001_0002_0_0004 m1 : 15|16@0+ (1,0) [0|0] "" Vector__XXX
 SG_ value m0 : 15|8@0+ (1,0) [0|0] "" Vector__XXX
 SG_ configuration M : 7|8@0+ (1,0) [0|0] ""  orin

BO_ 112 brp_all_stop: 0 orin

BO_ 113 brp_twitch_forward: 0 orin

BO_ 114 brp_twitch_backward: 0 orin

BO_ 115 brp_drive_at_speed: 2 orin
 SG_ velocity : 7|16@0- (1,0) [0|0] ""  back_right_pivot

BO_ 116 brp_drive_to_position: 2 orin
 SG_ position : 7|16@0- (1,0) [0|0] ""  back_right_pivot

BO_ 117 brp_drive_at_current: 2 orin
 SG_ effort : 7|16@0- (1,0) [0|0] ""  back_right_pivot

BO_ 118 brp_drive_open_loop: 4 orin
 SG_ open_loop_velocity : 23|16@0- (1,0) [0|0] ""  back_right_pivot
 SG_ open_loop_current : 7|16@0- (1,0) [0|0] ""  back_right_pivot

BO_ 119 brp_home_rotor: 0 orin

BO_ 120 brp_zero_resolver: 0 orin

BO_ 121 brp_get_configuration: 1 orin
 SG_ configuration : 7|8@0- (1,0) [0|0] ""  back_right_pivot

BO_ 122 brp_set_configuration: 4 orin
 SG_ shift_amount_0000_0001_0002_0004 m9 : 31|8@0+ (1,0) [0|0] "" Vector__XXX
 SG_ shift_amount_0000_0001_0002_0004 m8 : 31|8@0+ (1,0) [0|0] "" Vector__XXX
 SG_ shift_amount_0000_0001_0002_0004 m5 : 31|8@0+ (1,0) [0|0] "" Vector__XXX
 SG_ shift_amount_0000_0001_0002_0004 m4 : 31|8@0+ (1,0) [0|0] "" Vector__XXX
 SG_ shift_amount_0000_0001_0002_0004 m2 : 31|8@0+ (1,0) [0|0] "" Vector__XXX
 SG_ shift_amount_0000_0001_0002_0004 m1 : 31|8@0+ (1,0) [0|0] "" Vector__XXX
 SG_ speed_0000_0001_0002 m14 : 15|8@0+ (1,0) [0|0] "" Vector__XXX
 SG_ speed_0000_0001_0002 m13 : 15|8@0+ (1,0) [0|0] "" Vector__XXX
 SG_ speed_0000_0001_0002 m12 : 15|8@0+ (1,0) [0|0] "" Vector__XXX
 SG_ speed_0000_0001_0002 m11 : 15|8@0+ (1,0) [0|0] "" Vector__XXX
 SG_ max_position m10 : 15|16@0+ (1,0) [0|0] "" Vector__XXX
 SG_ fractional_0000_0001_0002_0_0004 m9 : 15|16@0+ (1,0) [0|0] "" Vector__XXX
 SG_ fractional_0000_0001_0002_0_0004 m8 : 15|16@0+ (1,0) [0|0] "" Vector__XXX
 SG_ min_interval m7 : 15|16@0+ (1,0) [0|0] "" Vector__XXX
 SG_ max_velocity m6 : 15|16@0+ (1,0) [0|0] "" Vector__XXX
 SG_ fractional_0000_0001_0002_0_0004 m5 : 15|16@0+ (1,0) [0|0] "" Vector__XXX
 SG_ fractional_0000_0001_0002_0_0004 m4 : 15|16@0+ (1,0) [0|0] "" Vector__XXX
 SG_ max_current m3 : 15|16@0+ (1,0) [0|0] "" Vector__XXX
 SG_ fractional_0000_0001_0002_0_0004 m2 : 15|16@0+ (1,0) [0|0] "" Vector__XXX
 SG_ fractional_0000_0001_0002_0_0004 m1 : 15|16@0+ (1,0) [0|0] "" Vector__XXX
 SG_ value m0 : 15|8@0+ (1,0) [0|0] "" Vector__XXX
 SG_ configuration M : 7|8@0+ (1,0) [0|0] ""  back_right_pivot

BO_ 123 brp_reset_blcmd: 0 orin

BO_ 124 brp_reset_resolver: 0 orin

BO_ 125 brp_read_gate_driver_fault: 0 orin

BO_ 1137 brp_telemetry_packet_1: 4 back_right_pivot
 SG_ q_current : 23|16@0- (1,0) [0|0] ""  orin
 SG_ velocity : 7|16@0- (1,0) [0|0] ""  orin

BO_ 1138 brp_telemetry_packet_2: 4 back_right_pivot
 SG_ d_current : 23|16@0- (1,0) [0|0] ""  orin
 SG_ interval : 7|16@0- (1,0) [0|0] ""  orin

BO_ 1139 brp_telemetry_packet_3: 4 back_right_pivot
 SG_ resolver_velocity : 23|16@0- (1,0) [0|0] ""  orin
 SG_ resolver_position : 7|16@0- (1,0) [0|0] ""  orin

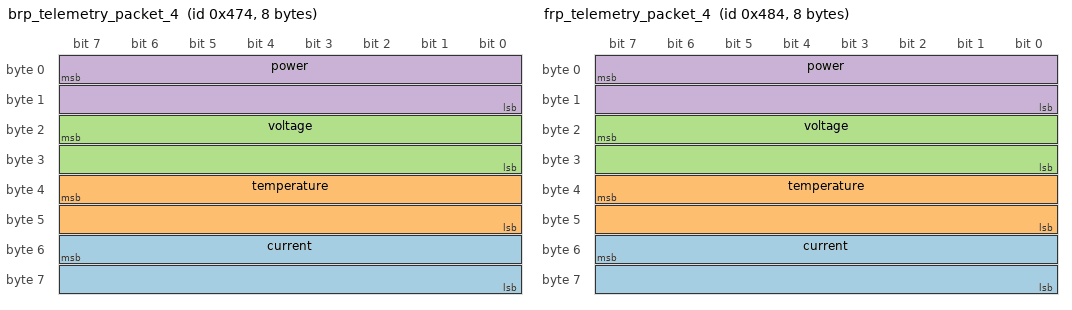
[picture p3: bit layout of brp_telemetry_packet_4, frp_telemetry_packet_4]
BO_ 1140 brp_telemetry_packet_4: 8 back_right_pivot
 SG_ current : 55|16@0- (1,0) [0|0] ""  orin
 SG_ temperature : 39|16@0- (1,0) [0|0] ""  orin
 SG_ voltage : 23|16@0- (1,0) [0|0] ""  orin
 SG_ power : 7|16@0- (1,0) [0|0] ""  orin

BO_ 1136 brp_log: 2 back_right_pivot
 SG_ gate_driver_condition m3 : 15|8@0+ (1,0) [0|0] "" Vector__XXX
 SG_ info_message m2 : 15|8@0- (1,0) [0|0] "" Vector__XXX
 SG_ warning_message m1 : 15|8@0- (1,0) [0|0] "" Vector__XXX
 SG_ error_message m0 : 15|8@0- (1,0) [0|0] "" Vector__XXX
 SG_ log_message M : 7|8@0- (1,0) [0|0] ""  orin

BO_ 1145 brp_current_configuration: 4 back_right_pivot
 SG_ shift_amount_0000_0001_0002_0004 m9 : 31|8@0+ (1,0) [0|0] "" Vector__XXX
 SG_ shift_amount_0000_0001_0002_0004 m8 : 31|8@0+ (1,0) [0|0] "" Vector__XXX
 SG_ shift_amount_0000_0001_0002_0004 m5 : 31|8@0+ (1,0) [0|0] "" Vector__XXX
 SG_ shift_amount_0000_0001_0002_0004 m4 : 31|8@0+ (1,0) [0|0] "" Vector__XXX
 SG_ shift_amount_0000_0001_0002_0004 m2 : 31|8@0+ (1,0) [0|0] "" Vector__XXX
 SG_ shift_amount_0000_0001_0002_0004 m1 : 31|8@0+ (1,0) [0|0] "" Vector__XXX
 SG_ speed_0000_0001_0002 m14 : 15|8@0+ (1,0) [0|0] "" Vector__XXX
 SG_ speed_0000_0001_0002 m13 : 15|8@0+ (1,0) [0|0] "" Vector__XXX
 SG_ speed_0000_0001_0002 m12 : 15|8@0+ (1,0) [0|0] "" Vector__XXX
 SG_ speed_0000_0001_0002 m11 : 15|8@0+ (1,0) [0|0] "" Vector__XXX
 SG_ max_position m10 : 15|16@0+ (1,0) [0|0] "" Vector__XXX
 SG_ fractional_0000_0001_0002_0_0004 m9 : 15|16@0+ (1,0) [0|0] "" Vector__XXX
 SG_ fractional_0000_0001_0002_0_0004 m8 : 15|16@0+ (1,0) [0|0] "" Vector__XXX
 SG_ min_interval m7 : 15|16@0+ (1,0) [0|0] "" Vector__XXX
 SG_ max_velocity m6 : 15|16@0+ (1,0) [0|0] "" Vector__XXX
 SG_ fractional_0000_0001_0002_0_0004 m5 : 15|16@0+ (1,0) [0|0] "" Vector__XXX
 SG_ fractional_0000_0001_0002_0_0004 m4 : 15|16@0+ (1,0) [0|0] "" Vector__XXX
 SG_ max_current m3 : 15|16@0+ (1,0) [0|0] "" Vector__XXX
 SG_ fractional_0000_0001_0002_0_0004 m2 : 15|16@0+ (1,0) [0|0] "" Vector__XXX
 SG_ fractional_0000_0001_0002_0_0004 m1 : 15|16@0+ (1,0) [0|0] "" Vector__XXX
 SG_ value m0 : 15|8@0+ (1,0) [0|0] "" Vector__XXX
 SG_ configuration M : 7|8@0+ (1,0) [0|0] ""  orin

BO_ 128 frp_all_stop: 0 orin

BO_ 129 frp_twitch_forward: 0 orin

BO_ 130 frp_twitch_backward: 0 orin

BO_ 131 frp_drive_at_speed: 2 orin
 SG_ velocity : 7|16@0- (1,0) [0|0] ""  front_right_pivot

BO_ 132 frp_drive_to_position: 2 orin
 SG_ position : 7|16@0- (1,0) [0|0] ""  front_right_pivot

BO_ 133 frp_drive_at_current: 2 orin
 SG_ effort : 7|16@0- (1,0) [0|0] ""  front_right_pivot

BO_ 134 frp_drive_open_loop: 4 orin
 SG_ open_loop_velocity : 23|16@0- (1,0) [0|0] ""  front_right_pivot
 SG_ open_loop_current : 7|16@0- (1,0) [0|0] ""  front_right_pivot

BO_ 135 frp_home_rotor: 0 orin

BO_ 136 frp_zero_resolver: 0 orin

BO_ 137 frp_get_configuration: 1 orin
 SG_ configuration : 7|8@0- (1,0) [0|0] ""  front_right_pivot

BO_ 138 frp_set_configuration: 4 orin
 SG_ shift_amount_0000_0001_0002_0004 m9 : 31|8@0+ (1,0) [0|0] "" Vector__XXX
 SG_ shift_amount_0000_0001_0002_0004 m8 : 31|8@0+ (1,0) [0|0] "" Vector__XXX
 SG_ shift_amount_0000_0001_0002_0004 m5 : 31|8@0+ (1,0) [0|0] "" Vector__XXX
 SG_ shift_amount_0000_0001_0002_0004 m4 : 31|8@0+ (1,0) [0|0] "" Vector__XXX
 SG_ shift_amount_0000_0001_0002_0004 m2 : 31|8@0+ (1,0) [0|0] "" Vector__XXX
 SG_ shift_amount_0000_0001_0002_0004 m1 : 31|8@0+ (1,0) [0|0] "" Vector__XXX
 SG_ speed_0000_0001_0002 m14 : 15|8@0+ (1,0) [0|0] "" Vector__XXX
 SG_ speed_0000_0001_0002 m13 : 15|8@0+ (1,0) [0|0] "" Vector__XXX
 SG_ speed_0000_0001_0002 m12 : 15|8@0+ (1,0) [0|0] "" Vector__XXX
 SG_ speed_0000_0001_0002 m11 : 15|8@0+ (1,0) [0|0] "" Vector__XXX
 SG_ max_position m10 : 15|16@0+ (1,0) [0|0] "" Vector__XXX
 SG_ fractional_0000_0001_0002_0_0004 m9 : 15|16@0+ (1,0) [0|0] "" Vector__XXX
 SG_ fractional_0000_0001_0002_0_0004 m8 : 15|16@0+ (1,0) [0|0] "" Vector__XXX
 SG_ min_interval m7 : 15|16@0+ (1,0) [0|0] "" Vector__XXX
 SG_ max_velocity m6 : 15|16@0+ (1,0) [0|0] "" Vector__XXX
 SG_ fractional_0000_0001_0002_0_0004 m5 : 15|16@0+ (1,0) [0|0] "" Vector__XXX
 SG_ fractional_0000_0001_0002_0_0004 m4 : 15|16@0+ (1,0) [0|0] "" Vector__XXX
 SG_ max_current m3 : 15|16@0+ (1,0) [0|0] "" Vector__XXX
 SG_ fractional_0000_0001_0002_0_0004 m2 : 15|16@0+ (1,0) [0|0] "" Vector__XXX
 SG_ fractional_0000_0001_0002_0_0004 m1 : 15|16@0+ (1,0) [0|0] "" Vector__XXX
 SG_ value m0 : 15|8@0+ (1,0) [0|0] "" Vector__XXX
 SG_ configuration M : 7|8@0+ (1,0) [0|0] ""  front_right_pivot

BO_ 139 frp_reset_blcmd: 0 orin

BO_ 140 frp_reset_resolver: 0 orin

BO_ 141 frp_read_gate_driver_fault: 0 orin

BO_ 1153 frp_telemetry_packet_1: 4 front_right_pivot
 SG_ q_current : 23|16@0- (1,0) [0|0] ""  orin
 SG_ velocity : 7|16@0- (1,0) [0|0] ""  orin

BO_ 1154 frp_telemetry_packet_2: 4 front_right_pivot
 SG_ d_current : 23|16@0- (1,0) [0|0] ""  orin
 SG_ interval : 7|16@0- (1,0) [0|0] ""  orin

BO_ 1155 frp_telemetry_packet_3: 4 front_right_pivot
 SG_ resolver_velocity : 23|16@0- (1,0) [0|0] ""  orin
 SG_ resolver_position : 7|16@0- (1,0) [0|0] ""  orin

BO_ 1156 frp_telemetry_packet_4: 8 front_right_pivot
 SG_ current : 55|16@0- (1,0) [0|0] ""  orin
 SG_ temperature : 39|16@0- (1,0) [0|0] ""  orin
 SG_ voltage : 23|16@0- (1,0) [0|0] ""  orin
 SG_ power : 7|16@0- (1,0) [0|0] ""  orin

BO_ 1152 frp_log: 2 front_right_pivot
 SG_ gate_driver_condition m3 : 15|8@0+ (1,0) [0|0] "" Vector__XXX
 SG_ info_message m2 : 15|8@0- (1,0) [0|0] "" Vector__XXX
 SG_ warning_message m1 : 15|8@0- (1,0) [0|0] "" Vector__XXX
 SG_ error_message m0 : 15|8@0- (1,0) [0|0] "" Vector__XXX
 SG_ log_message M : 7|8@0- (1,0) [0|0] ""  orin

BO_ 1161 frp_current_configuration: 4 front_right_pivot
 SG_ shift_amount_0000_0001_0002_0004 m9 : 31|8@0+ (1,0) [0|0] "" Vector__XXX
 SG_ shift_amount_0000_0001_0002_0004 m8 : 31|8@0+ (1,0) [0|0] "" Vector__XXX
 SG_ shift_amount_0000_0001_0002_0004 m5 : 31|8@0+ (1,0) [0|0] "" Vector__XXX
 SG_ shift_amount_0000_0001_0002_0004 m4 : 31|8@0+ (1,0) [0|0] "" Vector__XXX
 SG_ shift_amount_0000_0001_0002_0004 m2 : 31|8@0+ (1,0) [0|0] "" Vector__XXX
 SG_ shift_amount_0000_0001_0002_0004 m1 : 31|8@0+ (1,0) [0|0] "" Vector__XXX
 SG_ speed_0000_0001_0002 m14 : 15|8@0+ (1,0) [0|0] "" Vector__XXX
 SG_ speed_0000_0001_0002 m13 : 15|8@0+ (1,0) [0|0] "" Vector__XXX
 SG_ speed_0000_0001_0002 m12 : 15|8@0+ (1,0) [0|0] "" Vector__XXX
 SG_ speed_0000_0001_0002 m11 : 15|8@0+ (1,0) [0|0] "" Vector__XXX
 SG_ max_position m10 : 15|16@0+ (1,0) [0|0] "" Vector__XXX
 SG_ fractional_0000_0001_0002_0_0004 m9 : 15|16@0+ (1,0) [0|0] "" Vector__XXX
 SG_ fractional_0000_0001_0002_0_0004 m8 : 15|16@0+ (1,0) [0|0] "" Vector__XXX
 SG_ min_interval m7 : 15|16@0+ (1,0) [0|0] "" Vector__XXX
 SG_ max_velocity m6 : 15|16@0+ (1,0) [0|0] "" Vector__XXX
 SG_ fractional_0000_0001_0002_0_0004 m5 : 15|16@0+ (1,0) [0|0] "" Vector__XXX
 SG_ fractional_0000_0001_0002_0_0004 m4 : 15|16@0+ (1,0) [0|0] "" Vector__XXX
 SG_ max_current m3 : 15|16@0+ (1,0) [0|0] "" Vector__XXX
 SG_ fractional_0000_0001_0002_0_0004 m2 : 15|16@0+ (1,0) [0|0] "" Vector__XXX
 SG_ fractional_0000_0001_0002_0_0004 m1 : 15|16@0+ (1,0) [0|0] "" Vector__XXX
 SG_ value m0 : 15|8@0+ (1,0) [0|0] "" Vector__XXX
 SG_ configuration M : 7|8@0+ (1,0) [0|0] ""  orin

BA_DEF_ SG_  "SystemSignalLongSymbol" STRING ;
BA_DEF_DEF_  "SystemSignalLongSymbol" "";
BA_ "SystemSignalLongSymbol" SG_ 26 shift_amount_0000_0001_0002_0004 "shift_amount";
BA_ "SystemSignalLongSymbol" SG_ 26 shift_amount_0000_0001_0002_0004 "shift_amount";
BA_ "SystemSignalLongSymbol" SG_ 26 shift_amount_0000_0001_0002_0004 "shift_amount";
BA_ "SystemSignalLongSymbol" SG_ 26 shift_amount_0000_0001_0002_0004 "shift_amount";
BA_ "SystemSignalLongSymbol" SG_ 26 shift_amount_0000_0001_0002_0004 "shift_amount";
BA_ "SystemSignalLongSymbol" SG_ 26 shift_amount_0000_0001_0002_0004 "shift_amount";
BA_ "SystemSignalLongSymbol" SG_ 26 speed_0000_0001_0002 "speed";
BA_ "SystemSignalLongSymbol" SG_ 26 speed_0000_0001_0002 "speed";
BA_ "SystemSignalLongSymbol" SG_ 26 speed_0000_0001_0002 "speed";
BA_ "SystemSignalLongSymbol" SG_ 26 speed_0000_0001_0002 "speed";
BA_ "SystemSignalLongSymbol" SG_ 26 fractional_0000_0001_0002_0_0004 "fractional";
BA_ "SystemSignalLongSymbol" SG_ 26 fractional_0000_0001_0002_0_0004 "fractional";
BA_ "SystemSignalLongSymbol" SG_ 26 fractional_0000_0001_0002_0_0004 "fractional";
BA_ "SystemSignalLongSymbol" SG_ 26 fractional_0000_0001_0002_0_0004 "fractional";
BA_ "SystemSignalLongSymbol" SG_ 26 fractional_0000_0001_0002_0_0004 "fractional";
BA_ "SystemSignalLongSymbol" SG_ 26 fractional_0000_0001_0002_0_0004 "fractional";
BA_ "SystemSignalLongSymbol" SG_ 1049 shift_amount_0000_0001_0002_0004 "shift_amount";
BA_ "SystemSignalLongSymbol" SG_ 1049 shift_amount_0000_0001_0002_0004 "shift_amount";
BA_ "SystemSignalLongSymbol" SG_ 1049 shift_amount_0000_0001_0002_0004 "shift_amount";
BA_ "SystemSignalLongSymbol" SG_ 1049 shift_amount_0000_0001_0002_0004 "shift_amount";
BA_ "SystemSignalLongSymbol" SG_ 1049 shift_amount_0000_0001_0002_0004 "shift_amount";
BA_ "SystemSignalLongSymbol" SG_ 1049 shift_amount_0000_0001_0002_0004 "shift_amount";
BA_ "SystemSignalLongSymbol" SG_ 1049 speed_0000_0001_0002 "speed";
BA_ "SystemSignalLongSymbol" SG_ 1049 speed_0000_0001_0002 "speed";
BA_ "SystemSignalLongSymbol" SG_ 1049 speed_0000_0001_0002 "speed";
BA_ "SystemSignalLongSymbol" SG_ 1049 speed_0000_0001_0002 "speed";
BA_ "SystemSignalLongSymbol" SG_ 1049 fractional_0000_0001_0002_0_0004 "fractional";
BA_ "SystemSignalLongSymbol" SG_ 1049 fractional_0000_0001_0002_0_0004 "fractional";
BA_ "SystemSignalLongSymbol" SG_ 1049 fractional_0000_0001_0002_0_0004 "fractional";
BA_ "SystemSignalLongSymbol" SG_ 1049 fractional_0000_0001_0002_0_0004 "fractional";
BA_ "SystemSignalLongSymbol" SG_ 1049 fractional_0000_0001_0002_0_0004 "fractional";
BA_ "SystemSignalLongSymbol" SG_ 1049 fractional_0000_0001_0002_0_0004 "fractional";
BA_ "SystemSignalLongSymbol" SG_ 42 shift_amount_0000_0001_0002_0004 "shift_amount";
BA_ "SystemSignalLongSymbol" SG_ 42 shift_amount_0000_0001_0002_0004 "shift_amount";
BA_ "SystemSignalLongSymbol" SG_ 42 shift_amount_0000_0001_0002_0004 "shift_amount";
BA_ "SystemSignalLongSymbol" SG_ 42 shift_amount_0000_0001_0002_0004 "shift_amount";
BA_ "SystemSignalLongSymbol" SG_ 42 shift_amount_0000_0001_0002_0004 "shift_amount";
BA_ "SystemSignalLongSymbol" SG_ 42 shift_amount_0000_0001_0002_0004 "shift_amount";
BA_ "SystemSignalLongSymbol" SG_ 42 speed_0000_0001_0002 "speed";
BA_ "SystemSignalLongSymbol" SG_ 42 speed_0000_0001_0002 "speed";
BA_ "SystemSignalLongSymbol" SG_ 42 speed_0000_0001_0002 "speed";
BA_ "SystemSignalLongSymbol" SG_ 42 speed_0000_0001_0002 "speed";
BA_ "SystemSignalLongSymbol" SG_ 42 fractional_0000_0001_0002_0_0004 "fractional";
BA_ "SystemSignalLongSymbol" SG_ 42 fractional_0000_0001_0002_0_0004 "fractional";
BA_ "SystemSignalLongSymbol" SG_ 42 fractional_0000_0001_0002_0_0004 "fractional";
BA_ "SystemSignalLongSymbol" SG_ 42 fractional_0000_0001_0002_0_0004 "fractional";
BA_ "SystemSignalLongSymbol" SG_ 42 fractional_0000_0001_0002_0_0004 "fractional";
BA_ "SystemSignalLongSymbol" SG_ 42 fractional_0000_0001_0002_0_0004 "fractional";
BA_ "SystemSignalLongSymbol" SG_ 1065 shift_amount_0000_0001_0002_0004 "shift_amount";
BA_ "SystemSignalLongSymbol" SG_ 1065 shift_amount_0000_0001_0002_0004 "shift_amount";
BA_ "SystemSignalLongSymbol" SG_ 1065 shift_amount_0000_0001_0002_0004 "shift_amount";
BA_ "SystemSignalLongSymbol" SG_ 1065 shift_amount_0000_0001_0002_0004 "shift_amount";
BA_ "SystemSignalLongSymbol" SG_ 1065 shift_amount_0000_0001_0002_0004 "shift_amount";
BA_ "SystemSignalLongSymbol" SG_ 1065 shift_amount_0000_0001_0002_0004 "shift_amount";
BA_ "SystemSignalLongSymbol" SG_ 1065 speed_0000_0001_0002 "speed";
BA_ "SystemSignalLongSymbol" SG_ 1065 speed_0000_0001_0002 "speed";
BA_ "SystemSignalLongSymbol" SG_ 1065 speed_0000_0001_0002 "speed";
BA_ "SystemSignalLongSymbol" SG_ 1065 speed_0000_0001_0002 "speed";
BA_ "SystemSignalLongSymbol" SG_ 1065 fractional_0000_0001_0002_0_0004 "fractional";
BA_ "SystemSignalLongSymbol" SG_ 1065 fractional_0000_0001_0002_0_0004 "fractional";
BA_ "SystemSignalLongSymbol" SG_ 1065 fractional_0000_0001_0002_0_0004 "fractional";
BA_ "SystemSignalLongSymbol" SG_ 1065 fractional_0000_0001_0002_0_0004 "fractional";
BA_ "SystemSignalLongSymbol" SG_ 1065 fractional_0000_0001_0002_0_0004 "fractional";
BA_ "SystemSignalLongSymbol" SG_ 1065 fractional_0000_0001_0002_0_0004 "fractional";
BA_ "SystemSignalLongSymbol" SG_ 58 shift_amount_0000_0001_0002_0004 "shift_amount";
BA_ "SystemSignalLongSymbol" SG_ 58 shift_amount_0000_0001_0002_0004 "shift_amount";
BA_ "SystemSignalLongSymbol" SG_ 58 shift_amount_0000_0001_0002_0004 "shift_amount";
BA_ "SystemSignalLongSymbol" SG_ 58 shift_amount_0000_0001_0002_0004 "shift_amount";
BA_ "SystemSignalLongSymbol" SG_ 58 shift_amount_0000_0001_0002_0004 "shift_amount";
BA_ "SystemSignalLongSymbol" SG_ 58 shift_amount_0000_0001_0002_0004 "shift_amount";
BA_ "SystemSignalLongSymbol" SG_ 58 speed_0000_0001_0002 "speed";
BA_ "SystemSignalLongSymbol" SG_ 58 speed_0000_0001_0002 "speed";
BA_ "SystemSignalLongSymbol" SG_ 58 speed_0000_0001_0002 "speed";
BA_ "SystemSignalLongSymbol" SG_ 58 speed_0000_0001_0002 "speed";
BA_ "SystemSignalLongSymbol" SG_ 58 fractional_0000_0001_0002_0_0004 "fractional";
BA_ "SystemSignalLongSymbol" SG_ 58 fractional_0000_0001_0002_0_0004 "fractional";
BA_ "SystemSignalLongSymbol" SG_ 58 fractional_0000_0001_0002_0_0004 "fractional";
BA_ "SystemSignalLongSymbol" SG_ 58 fractional_0000_0001_0002_0_0004 "fractional";
BA_ "SystemSignalLongSymbol" SG_ 58 fractional_0000_0001_0002_0_0004 "fractional";
BA_ "SystemSignalLongSymbol" SG_ 58 fractional_0000_0001_0002_0_0004 "fractional";
BA_ "SystemSignalLongSymbol" SG_ 1081 shift_amount_0000_0001_0002_0004 "shift_amount";
BA_ "SystemSignalLongSymbol" SG_ 1081 shift_amount_0000_0001_0002_0004 "shift_amount";
BA_ "SystemSignalLongSymbol" SG_ 1081 shift_amount_0000_0001_0002_0004 "shift_amount";
BA_ "SystemSignalLongSymbol" SG_ 1081 shift_amount_0000_0001_0002_0004 "shift_amount";
BA_ "SystemSignalLongSymbol" SG_ 1081 shift_amount_0000_0001_0002_0004 "shift_amount";
BA_ "SystemSignalLongSymbol" SG_ 1081 shift_amount_0000_0001_0002_0004 "shift_amount";
BA_ "SystemSignalLongSymbol" SG_ 1081 speed_0000_0001_0002 "speed";
BA_ "SystemSignalLongSymbol" SG_ 1081 speed_0000_0001_0002 "speed";
BA_ "SystemSignalLongSymbol" SG_ 1081 speed_0000_0001_0002 "speed";
BA_ "SystemSignalLongSymbol" SG_ 1081 speed_0000_0001_0002 "speed";
BA_ "SystemSignalLongSymbol" SG_ 1081 fractional_0000_0001_0002_0_0004 "fractional";
BA_ "SystemSignalLongSymbol" SG_ 1081 fractional_0000_0001_0002_0_0004 "fractional";
BA_ "SystemSignalLongSymbol" SG_ 1081 fractional_0000_0001_0002_0_0004 "fractional";
BA_ "SystemSignalLongSymbol" SG_ 1081 fractional_0000_0001_0002_0_0004 "fractional";
BA_ "SystemSignalLongSymbol" SG_ 1081 fractional_0000_0001_0002_0_0004 "fractional";
BA_ "SystemSignalLongSymbol" SG_ 1081 fractional_0000_0001_0002_0_0004 "fractional";
BA_ "SystemSignalLongSymbol" SG_ 74 shift_amount_0000_0001_0002_0004 "shift_amount";
BA_ "SystemSignalLongSymbol" SG_ 74 shift_amount_0000_0001_0002_0004 "shift_amount";
BA_ "SystemSignalLongSymbol" SG_ 74 shift_amount_0000_0001_0002_0004 "shift_amount";
BA_ "SystemSignalLongSymbol" SG_ 74 shift_amount_0000_0001_0002_0004 "shift_amount";
BA_ "SystemSignalLongSymbol" SG_ 74 shift_amount_0000_0001_0002_0004 "shift_amount";
BA_ "SystemSignalLongSymbol" SG_ 74 shift_amount_0000_0001_0002_0004 "shift_amount";
BA_ "SystemSignalLongSymbol" SG_ 74 speed_0000_0001_0002 "speed";
BA_ "SystemSignalLongSymbol" SG_ 74 speed_0000_0001_0002 "speed";
BA_ "SystemSignalLongSymbol" SG_ 74 speed_0000_0001_0002 "speed";
BA_ "SystemSignalLongSymbol" SG_ 74 speed_0000_0001_0002 "speed";
BA_ "SystemSignalLongSymbol" SG_ 74 fractional_0000_0001_0002_0_0004 "fractional";
BA_ "SystemSignalLongSymbol" SG_ 74 fractional_0000_0001_0002_0_0004 "fractional";
BA_ "SystemSignalLongSymbol" SG_ 74 fractional_0000_0001_0002_0_0004 "fractional";
BA_ "SystemSignalLongSymbol" SG_ 74 fractional_0000_0001_0002_0_0004 "fractional";
BA_ "SystemSignalLongSymbol" SG_ 74 fractional_0000_0001_0002_0_0004 "fractional";
BA_ "SystemSignalLongSymbol" SG_ 74 fractional_0000_0001_0002_0_0004 "fractional";
BA_ "SystemSignalLongSymbol" SG_ 1097 shift_amount_0000_0001_0002_0004 "shift_amount";
BA_ "SystemSignalLongSymbol" SG_ 1097 shift_amount_0000_0001_0002_0004 "shift_amount";
BA_ "SystemSignalLongSymbol" SG_ 1097 shift_amount_0000_0001_0002_0004 "shift_amount";
BA_ "SystemSignalLongSymbol" SG_ 1097 shift_amount_0000_0001_0002_0004 "shift_amount";
BA_ "SystemSignalLongSymbol" SG_ 1097 shift_amount_0000_0001_0002_0004 "shift_amount";
BA_ "SystemSignalLongSymbol" SG_ 1097 shift_amount_0000_0001_0002_0004 "shift_amount";
BA_ "SystemSignalLongSymbol" SG_ 1097 speed_0000_0001_0002 "speed";
BA_ "SystemSignalLongSymbol" SG_ 1097 speed_0000_0001_0002 "speed";
BA_ "SystemSignalLongSymbol" SG_ 1097 speed_0000_0001_0002 "speed";
BA_ "SystemSignalLongSymbol" SG_ 1097 speed_0000_0001_0002 "speed";
BA_ "SystemSignalLongSymbol" SG_ 1097 fractional_0000_0001_0002_0_0004 "fractional";
BA_ "SystemSignalLongSymbol" SG_ 1097 fractional_0000_0001_0002_0_0004 "fractional";
BA_ "SystemSignalLongSymbol" SG_ 1097 fractional_0000_0001_0002_0_0004 "fractional";
BA_ "SystemSignalLongSymbol" SG_ 1097 fractional_0000_0001_0002_0_0004 "fractional";
BA_ "SystemSignalLongSymbol" SG_ 1097 fractional_0000_0001_0002_0_0004 "fractional";
BA_ "SystemSignalLongSymbol" SG_ 1097 fractional_0000_0001_0002_0_0004 "fractional";
BA_ "SystemSignalLongSymbol" SG_ 90 shift_amount_0000_0001_0002_0004 "shift_amount";
BA_ "SystemSignalLongSymbol" SG_ 90 shift_amount_0000_0001_0002_0004 "shift_amount";
BA_ "SystemSignalLongSymbol" SG_ 90 shift_amount_0000_0001_0002_0004 "shift_amount";
BA_ "SystemSignalLongSymbol" SG_ 90 shift_amount_0000_0001_0002_0004 "shift_amount";
BA_ "SystemSignalLongSymbol" SG_ 90 shift_amount_0000_0001_0002_0004 "shift_amount";
BA_ "SystemSignalLongSymbol" SG_ 90 shift_amount_0000_0001_0002_0004 "shift_amount";
BA_ "SystemSignalLongSymbol" SG_ 90 speed_0000_0001_0002 "speed";
BA_ "SystemSignalLongSymbol" SG_ 90 speed_0000_0001_0002 "speed";
BA_ "SystemSignalLongSymbol" SG_ 90 speed_0000_0001_0002 "speed";
BA_ "SystemSignalLongSymbol" SG_ 90 speed_0000_0001_0002 "speed";
BA_ "SystemSignalLongSymbol" SG_ 90 fractional_0000_0001_0002_0_0004 "fractional";
BA_ "SystemSignalLongSymbol" SG_ 90 fractional_0000_0001_0002_0_0004 "fractional";
BA_ "SystemSignalLongSymbol" SG_ 90 fractional_0000_0001_0002_0_0004 "fractional";
BA_ "SystemSignalLongSymbol" SG_ 90 fractional_0000_0001_0002_0_0004 "fractional";
BA_ "SystemSignalLongSymbol" SG_ 90 fractional_0000_0001_0002_0_0004 "fractional";
BA_ "SystemSignalLongSymbol" SG_ 90 fractional_0000_0001_0002_0_0004 "fractional";
BA_ "SystemSignalLongSymbol" SG_ 1113 shift_amount_0000_0001_0002_0004 "shift_amount";
BA_ "SystemSignalLongSymbol" SG_ 1113 shift_amount_0000_0001_0002_0004 "shift_amount";
BA_ "SystemSignalLongSymbol" SG_ 1113 shift_amount_0000_0001_0002_0004 "shift_amount";
BA_ "SystemSignalLongSymbol" SG_ 1113 shift_amount_0000_0001_0002_0004 "shift_amount";
BA_ "SystemSignalLongSymbol" SG_ 1113 shift_amount_0000_0001_0002_0004 "shift_amount";
BA_ "SystemSignalLongSymbol" SG_ 1113 shift_amount_0000_0001_0002_0004 "shift_amount";
BA_ "SystemSignalLongSymbol" SG_ 1113 speed_0000_0001_0002 "speed";
BA_ "SystemSignalLongSymbol" SG_ 1113 speed_0000_0001_0002 "speed";
BA_ "SystemSignalLongSymbol" SG_ 1113 speed_0000_0001_0002 "speed";
BA_ "SystemSignalLongSymbol" SG_ 1113 speed_0000_0001_0002 "speed";
BA_ "SystemSignalLongSymbol" SG_ 1113 fractional_0000_0001_0002_0_0004 "fractional";
BA_ "SystemSignalLongSymbol" SG_ 1113 fractional_0000_0001_0002_0_0004 "fractional";
BA_ "SystemSignalLongSymbol" SG_ 1113 fractional_0000_0001_0002_0_0004 "fractional";
BA_ "SystemSignalLongSymbol" SG_ 1113 fractional_0000_0001_0002_0_0004 "fractional";
BA_ "SystemSignalLongSymbol" SG_ 1113 fractional_0000_0001_0002_0_0004 "fractional";
BA_ "SystemSignalLongSymbol" SG_ 1113 fractional_0000_0001_0002_0_0004 "fractional";
BA_ "SystemSignalLongSymbol" SG_ 106 shift_amount_0000_0001_0002_0004 "shift_amount";
BA_ "SystemSignalLongSymbol" SG_ 106 shift_amount_0000_0001_0002_0004 "shift_amount";
BA_ "SystemSignalLongSymbol" SG_ 106 shift_amount_0000_0001_0002_0004 "shift_amount";
BA_ "SystemSignalLongSymbol" SG_ 106 shift_amount_0000_0001_0002_0004 "shift_amount";
BA_ "SystemSignalLongSymbol" SG_ 106 shift_amount_0000_0001_0002_0004 "shift_amount";
BA_ "SystemSignalLongSymbol" SG_ 106 shift_amount_0000_0001_0002_0004 "shift_amount";
BA_ "SystemSignalLongSymbol" SG_ 106 speed_0000_0001_0002 "speed";
BA_ "SystemSignalLongSymbol" SG_ 106 speed_0000_0001_0002 "speed";
BA_ "SystemSignalLongSymbol" SG_ 106 speed_0000_0001_0002 "speed";
BA_ "SystemSignalLongSymbol" SG_ 106 speed_0000_0001_0002 "speed";
BA_ "SystemSignalLongSymbol" SG_ 106 fractional_0000_0001_0002_0_0004 "fractional";
BA_ "SystemSignalLongSymbol" SG_ 106 fractional_0000_0001_0002_0_0004 "fractional";
BA_ "SystemSignalLongSymbol" SG_ 106 fractional_0000_0001_0002_0_0004 "fractional";
BA_ "SystemSignalLongSymbol" SG_ 106 fractional_0000_0001_0002_0_0004 "fractional";
BA_ "SystemSignalLongSymbol" SG_ 106 fractional_0000_0001_0002_0_0004 "fractional";
BA_ "SystemSignalLongSymbol" SG_ 106 fractional_0000_0001_0002_0_0004 "fractional";
BA_ "SystemSignalLongSymbol" SG_ 1129 shift_amount_0000_0001_0002_0004 "shift_amount";
BA_ "SystemSignalLongSymbol" SG_ 1129 shift_amount_0000_0001_0002_0004 "shift_amount";
BA_ "SystemSignalLongSymbol" SG_ 1129 shift_amount_0000_0001_0002_0004 "shift_amount";
BA_ "SystemSignalLongSymbol" SG_ 1129 shift_amount_0000_0001_0002_0004 "shift_amount";
BA_ "SystemSignalLongSymbol" SG_ 1129 shift_amount_0000_0001_0002_0004 "shift_amount";
BA_ "SystemSignalLongSymbol" SG_ 1129 shift_amount_0000_0001_0002_0004 "shift_amount";
BA_ "SystemSignalLongSymbol" SG_ 1129 speed_0000_0001_0002 "speed";
BA_ "SystemSignalLongSymbol" SG_ 1129 speed_0000_0001_0002 "speed";
BA_ "SystemSignalLongSymbol" SG_ 1129 speed_0000_0001_0002 "speed";
BA_ "SystemSignalLongSymbol" SG_ 1129 speed_0000_0001_0002 "speed";
BA_ "SystemSignalLongSymbol" SG_ 1129 fractional_0000_0001_0002_0_0004 "fractional";
BA_ "SystemSignalLongSymbol" SG_ 1129 fractional_0000_0001_0002_0_0004 "fractional";
BA_ "SystemSignalLongSymbol" SG_ 1129 fractional_0000_0001_0002_0_0004 "fractional";
BA_ "SystemSignalLongSymbol" SG_ 1129 fractional_0000_0001_0002_0_0004 "fractional";
BA_ "SystemSignalLongSymbol" SG_ 1129 fractional_0000_0001_0002_0_0004 "fractional";
BA_ "SystemSignalLongSymbol" SG_ 1129 fractional_0000_0001_0002_0_0004 "fractional";
BA_ "SystemSignalLongSymbol" SG_ 122 shift_amount_0000_0001_0002_0004 "shift_amount";
BA_ "SystemSignalLongSymbol" SG_ 122 shift_amount_0000_0001_0002_0004 "shift_amount";
BA_ "SystemSignalLongSymbol" SG_ 122 shift_amount_0000_0001_0002_0004 "shift_amount";
BA_ "SystemSignalLongSymbol" SG_ 122 shift_amount_0000_0001_0002_0004 "shift_amount";
BA_ "SystemSignalLongSymbol" SG_ 122 shift_amount_0000_0001_0002_0004 "shift_amount";
BA_ "SystemSignalLongSymbol" SG_ 122 shift_amount_0000_0001_0002_0004 "shift_amount";
BA_ "SystemSignalLongSymbol" SG_ 122 speed_0000_0001_0002 "speed";
BA_ "SystemSignalLongSymbol" SG_ 122 speed_0000_0001_0002 "speed";
BA_ "SystemSignalLongSymbol" SG_ 122 speed_0000_0001_0002 "speed";
BA_ "SystemSignalLongSymbol" SG_ 122 speed_0000_0001_0002 "speed";
BA_ "SystemSignalLongSymbol" SG_ 122 fractional_0000_0001_0002_0_0004 "fractional";
BA_ "SystemSignalLongSymbol" SG_ 122 fractional_0000_0001_0002_0_0004 "fractional";
BA_ "SystemSignalLongSymbol" SG_ 122 fractional_0000_0001_0002_0_0004 "fractional";
BA_ "SystemSignalLongSymbol" SG_ 122 fractional_0000_0001_0002_0_0004 "fractional";
BA_ "SystemSignalLongSymbol" SG_ 122 fractional_0000_0001_0002_0_0004 "fractional";
BA_ "SystemSignalLongSymbol" SG_ 122 fractional_0000_0001_0002_0_0004 "fractional";
BA_ "SystemSignalLongSymbol" SG_ 1145 shift_amount_0000_0001_0002_0004 "shift_amount";
BA_ "SystemSignalLongSymbol" SG_ 1145 shift_amount_0000_0001_0002_0004 "shift_amount";
BA_ "SystemSignalLongSymbol" SG_ 1145 shift_amount_0000_0001_0002_0004 "shift_amount";
BA_ "SystemSignalLongSymbol" SG_ 1145 shift_amount_0000_0001_0002_0004 "shift_amount";
BA_ "SystemSignalLongSymbol" SG_ 1145 shift_amount_0000_0001_0002_0004 "shift_amount";
BA_ "SystemSignalLongSymbol" SG_ 1145 shift_amount_0000_0001_0002_0004 "shift_amount";
BA_ "SystemSignalLongSymbol" SG_ 1145 speed_0000_0001_0002 "speed";
BA_ "SystemSignalLongSymbol" SG_ 1145 speed_0000_0001_0002 "speed";
BA_ "SystemSignalLongSymbol" SG_ 1145 speed_0000_0001_0002 "speed";
BA_ "SystemSignalLongSymbol" SG_ 1145 speed_0000_0001_0002 "speed";
BA_ "SystemSignalLongSymbol" SG_ 1145 fractional_0000_0001_0002_0_0004 "fractional";
BA_ "SystemSignalLongSymbol" SG_ 1145 fractional_0000_0001_0002_0_0004 "fractional";
BA_ "SystemSignalLongSymbol" SG_ 1145 fractional_0000_0001_0002_0_0004 "fractional";
BA_ "SystemSignalLongSymbol" SG_ 1145 fractional_0000_0001_0002_0_0004 "fractional";
BA_ "SystemSignalLongSymbol" SG_ 1145 fractional_0000_0001_0002_0_0004 "fractional";
BA_ "SystemSignalLongSymbol" SG_ 1145 fractional_0000_0001_0002_0_0004 "fractional";
BA_ "SystemSignalLongSymbol" SG_ 138 shift_amount_0000_0001_0002_0004 "shift_amount";
BA_ "SystemSignalLongSymbol" SG_ 138 shift_amount_0000_0001_0002_0004 "shift_amount";
BA_ "SystemSignalLongSymbol" SG_ 138 shift_amount_0000_0001_0002_0004 "shift_amount";
BA_ "SystemSignalLongSymbol" SG_ 138 shift_amount_0000_0001_0002_0004 "shift_amount";
BA_ "SystemSignalLongSymbol" SG_ 138 shift_amount_0000_0001_0002_0004 "shift_amount";
BA_ "SystemSignalLongSymbol" SG_ 138 shift_amount_0000_0001_0002_0004 "shift_amount";
BA_ "SystemSignalLongSymbol" SG_ 138 speed_0000_0001_0002 "speed";
BA_ "SystemSignalLongSymbol" SG_ 138 speed_0000_0001_0002 "speed";
BA_ "SystemSignalLongSymbol" SG_ 138 speed_0000_0001_0002 "speed";
BA_ "SystemSignalLongSymbol" SG_ 138 speed_0000_0001_0002 "speed";
BA_ "SystemSignalLongSymbol" SG_ 138 fractional_0000_0001_0002_0_0004 "fractional";
BA_ "SystemSignalLongSymbol" SG_ 138 fractional_0000_0001_0002_0_0004 "fractional";
BA_ "SystemSignalLongSymbol" SG_ 138 fractional_0000_0001_0002_0_0004 "fractional";
BA_ "SystemSignalLongSymbol" SG_ 138 fractional_0000_0001_0002_0_0004 "fractional";
BA_ "SystemSignalLongSymbol" SG_ 138 fractional_0000_0001_0002_0_0004 "fractional";
BA_ "SystemSignalLongSymbol" SG_ 138 fractional_0000_0001_0002_0_0004 "fractional";
BA_ "SystemSignalLongSymbol" SG_ 1161 shift_amount_0000_0001_0002_0004 "shift_amount";
BA_ "SystemSignalLongSymbol" SG_ 1161 shift_amount_0000_0001_0002_0004 "shift_amount";
BA_ "SystemSignalLongSymbol" SG_ 1161 shift_amount_0000_0001_0002_0004 "shift_amount";
BA_ "SystemSignalLongSymbol" SG_ 1161 shift_amount_0000_0001_0002_0004 "shift_amount";
BA_ "SystemSignalLongSymbol" SG_ 1161 shift_amount_0000_0001_0002_0004 "shift_amount";
BA_ "SystemSignalLongSymbol" SG_ 1161 shift_amount_0000_0001_0002_0004 "shift_amount";
BA_ "SystemSignalLongSymbol" SG_ 1161 speed_0000_0001_0002 "speed";
BA_ "SystemSignalLongSymbol" SG_ 1161 speed_0000_0001_0002 "speed";
BA_ "SystemSignalLongSymbol" SG_ 1161 speed_0000_0001_0002 "speed";
BA_ "SystemSignalLongSymbol" SG_ 1161 speed_0000_0001_0002 "speed";
BA_ "SystemSignalLongSymbol" SG_ 1161 fractional_0000_0001_0002_0_0004 "fractional";
BA_ "SystemSignalLongSymbol" SG_ 1161 fractional_0000_0001_0002_0_0004 "fractional";
BA_ "SystemSignalLongSymbol" SG_ 1161 fractional_0000_0001_0002_0_0004 "fractional";
BA_ "SystemSignalLongSymbol" SG_ 1161 fractional_0000_0001_0002_0_0004 "fractional";
BA_ "SystemSignalLongSymbol" SG_ 1161 fractional_0000_0001_0002_0_0004 "fractional";
BA_ "SystemSignalLongSymbol" SG_ 1161 fractional_0000_0001_0002_0_0004 "fractional";
VAL_ 25 configuration 0 "has_resolver" 1 "current_kp" 2 "current_ki" 3 "max_current_threshold" 4 "velocity_kp" 5 "velocity_ki" 6 "max_velocity_threshold" 7 "min_interval" 8 "position_kp" 9 "position_ki" 10 "max_position_threshold" 11 "telemetry_packet_1_speed" 12 "telemetry_packet_2_speed" 13 "telemetry_packet_3_speed" 14 "telemetry_packet_4_speed" ;
VAL_ 26 value 0 "false" 1 "true" ;
VAL_ 26 configuration 0 "has_resolver" 1 "current_kp" 2 "current_ki" 3 "max_current_threshold" 4 "velocity_kp" 5 "velocity_ki" 6 "max_velocity_threshold" 7 "min_interval" 8 "position_kp" 9 "position_ki" 10 "max_position_threshold" 11 "telemetry_packet_1_speed" 12 "telemetry_packet_2_speed" 13 "telemetry_packet_3_speed" 14 "telemetry_packet_4_speed" ;
VAL_ 1040 gate_driver_condition 255 "log_sequence_complete" ;
VAL_ 1040 info_message 0 "gate_driver_config_success" 1 "ma302_config_success" 2 "gate_driver_fault_recovered" 3 "rotor_home_success" 4 "resolver_zero_success" ;
VAL_ 1040 warning_message 0 "missing_steps" 1 "duty_cycle_threshold" 2 "current_threshold" 3 "velocity_threshold" 4 "position_out_of_range" ;
VAL_ 1040 error_message 0 "no_steps" 1 "magnetic_encoder_error" 2 "resolver_error" 3 "resolver_failed_checksum" 4 "unexpected_position_command" 5 "gate_driver_fault" 6 "gate_driver_spi_failed" 7 "ma302_spi_failed" 8 "rotor_home_failed" 9 "resolver_zero_failure" 10 "stall_triggered" 11 "over_speed" 12 "over_acceleration" 13 "encoder_fault" ;
VAL_ 1040 log_message 0 "error" 1 "warning" 2 "info" 3 "gate_driver_condition" ;
VAL_ 1049 value 0 "false" 1 "true" ;
VAL_ 1049 configuration 0 "has_resolver" 1 "current_kp" 2 "current_ki" 3 "max_current_threshold" 4 "velocity_kp" 5 "velocity_ki" 6 "max_velocity_threshold" 7 "min_interval" 8 "position_kp" 9 "position_ki" 10 "max_position_threshold" 11 "telemetry_packet_1_speed" 12 "telemetry_packet_2_speed" 13 "telemetry_packet_3_speed" 14 "telemetry_packet_4_speed" ;
VAL_ 41 configuration 0 "has_resolver" 1 "current_kp" 2 "current_ki" 3 "max_current_threshold" 4 "velocity_kp" 5 "velocity_ki" 6 "max_velocity_threshold" 7 "min_interval" 8 "position_kp" 9 "position_ki" 10 "max_position_threshold" 11 "telemetry_packet_1_speed" 12 "telemetry_packet_2_speed" 13 "telemetry_packet_3_speed" 14 "telemetry_packet_4_speed" ;
VAL_ 42 value 0 "false" 1 "true" ;
VAL_ 42 configuration 0 "has_resolver" 1 "current_kp" 2 "current_ki" 3 "max_current_threshold" 4 "velocity_kp" 5 "velocity_ki" 6 "max_velocity_threshold" 7 "min_interval" 8 "position_kp" 9 "position_ki" 10 "max_position_threshold" 11 "telemetry_packet_1_speed" 12 "telemetry_packet_2_speed" 13 "telemetry_packet_3_speed" 14 "telemetry_packet_4_speed" ;
VAL_ 1056 gate_driver_condition 255 "log_sequence_complete" ;
VAL_ 1056 info_message 0 "gate_driver_config_success" 1 "ma302_config_success" 2 "gate_driver_fault_recovered" 3 "rotor_home_success" 4 "resolver_zero_success" ;
VAL_ 1056 warning_message 0 "missing_steps" 1 "duty_cycle_threshold" 2 "current_threshold" 3 "velocity_threshold" 4 "position_out_of_range" ;
VAL_ 1056 error_message 0 "no_steps" 1 "magnetic_encoder_error" 2 "resolver_error" 3 "resolver_failed_checksum" 4 "unexpected_position_command" 5 "gate_driver_fault" 6 "gate_driver_spi_failed" 7 "ma302_spi_failed" 8 "rotor_home_failed" 9 "resolver_zero_failure" 10 "stall_triggered" 11 "over_speed" 12 "over_acceleration" 13 "encoder_fault" ;
VAL_ 1056 log_message 0 "error" 1 "warning" 2 "info" 3 "gate_driver_condition" ;
VAL_ 1065 value 0 "false" 1 "true" ;
VAL_ 1065 configuration 0 "has_resolver" 1 "current_kp" 2 "current_ki" 3 "max_current_threshold" 4 "velocity_kp" 5 "velocity_ki" 6 "max_velocity_threshold" 7 "min_interval" 8 "position_kp" 9 "position_ki" 10 "max_position_threshold" 11 "telemetry_packet_1_speed" 12 "telemetry_packet_2_speed" 13 "telemetry_packet_3_speed" 14 "telemetry_packet_4_speed" ;
VAL_ 57 configuration 0 "has_resolver" 1 "current_kp" 2 "current_ki" 3 "max_current_threshold" 4 "velocity_kp" 5 "velocity_ki" 6 "max_velocity_threshold" 7 "min_interval" 8 "position_kp" 9 "position_ki" 10 "max_position_threshold" 11 "telemetry_packet_1_speed" 12 "telemetry_packet_2_speed" 13 "telemetry_packet_3_speed" 14 "telemetry_packet_4_speed" ;
VAL_ 58 value 0 "false" 1 "true" ;
VAL_ 58 configuration 0 "has_resolver" 1 "current_kp" 2 "current_ki" 3 "max_current_threshold" 4 "velocity_kp" 5 "velocity_ki" 6 "max_velocity_threshold" 7 "min_interval" 8 "position_kp" 9 "position_ki" 10 "max_position_threshold" 11 "telemetry_packet_1_speed" 12 "telemetry_packet_2_speed" 13 "telemetry_packet_3_speed" 14 "telemetry_packet_4_speed" ;
VAL_ 1072 gate_driver_condition 255 "log_sequence_complete" ;
VAL_ 1072 info_message 0 "gate_driver_config_success" 1 "ma302_config_success" 2 "gate_driver_fault_recovered" 3 "rotor_home_success" 4 "resolver_zero_success" ;
VAL_ 1072 warning_message 0 "missing_steps" 1 "duty_cycle_threshold" 2 "current_threshold" 3 "velocity_threshold" 4 "position_out_of_range" ;
VAL_ 1072 error_message 0 "no_steps" 1 "magnetic_encoder_error" 2 "resolver_error" 3 "resolver_failed_checksum" 4 "unexpected_position_command" 5 "gate_driver_fault" 6 "gate_driver_spi_failed" 7 "ma302_spi_failed" 8 "rotor_home_failed" 9 "resolver_zero_failure" 10 "stall_triggered" 11 "over_speed" 12 "over_acceleration" 13 "encoder_fault" ;
VAL_ 1072 log_message 0 "error" 1 "warning" 2 "info" 3 "gate_driver_condition" ;
VAL_ 1081 value 0 "false" 1 "true" ;
VAL_ 1081 configuration 0 "has_resolver" 1 "current_kp" 2 "current_ki" 3 "max_current_threshold" 4 "velocity_kp" 5 "velocity_ki" 6 "max_velocity_threshold" 7 "min_interval" 8 "position_kp" 9 "position_ki" 10 "max_position_threshold" 11 "telemetry_packet_1_speed" 12 "telemetry_packet_2_speed" 13 "telemetry_packet_3_speed" 14 "telemetry_packet_4_speed" ;
VAL_ 73 configuration 0 "has_resolver" 1 "current_kp" 2 "current_ki" 3 "max_current_threshold" 4 "velocity_kp" 5 "velocity_ki" 6 "max_velocity_threshold" 7 "min_interval" 8 "position_kp" 9 "position_ki" 10 "max_position_threshold" 11 "telemetry_packet_1_speed" 12 "telemetry_packet_2_speed" 13 "telemetry_packet_3_speed" 14 "telemetry_packet_4_speed" ;
VAL_ 74 value 0 "false" 1 "true" ;
VAL_ 74 configuration 0 "has_resolver" 1 "current_kp" 2 "current_ki" 3 "max_current_threshold" 4 "velocity_kp" 5 "velocity_ki" 6 "max_velocity_threshold" 7 "min_interval" 8 "position_kp" 9 "position_ki" 10 "max_position_threshold" 11 "telemetry_packet_1_speed" 12 "telemetry_packet_2_speed" 13 "telemetry_packet_3_speed" 14 "telemetry_packet_4_speed" ;
VAL_ 1088 gate_driver_condition 255 "log_sequence_complete" ;
VAL_ 1088 info_message 0 "gate_driver_config_success" 1 "ma302_config_success" 2 "gate_driver_fault_recovered" 3 "rotor_home_success" 4 "resolver_zero_success" ;
VAL_ 1088 warning_message 0 "missing_steps" 1 "duty_cycle_threshold" 2 "current_threshold" 3 "velocity_threshold" 4 "position_out_of_range" ;
VAL_ 1088 error_message 0 "no_steps" 1 "magnetic_encoder_error" 2 "resolver_error" 3 "resolver_failed_checksum" 4 "unexpected_position_command" 5 "gate_driver_fault" 6 "gate_driver_spi_failed" 7 "ma302_spi_failed" 8 "rotor_home_failed" 9 "resolver_zero_failure" 10 "stall_triggered" 11 "over_speed" 12 "over_acceleration" 13 "encoder_fault" ;
VAL_ 1088 log_message 0 "error" 1 "warning" 2 "info" 3 "gate_driver_condition" ;
VAL_ 1097 value 0 "false" 1 "true" ;
VAL_ 1097 configuration 0 "has_resolver" 1 "current_kp" 2 "current_ki" 3 "max_current_threshold" 4 "velocity_kp" 5 "velocity_ki" 6 "max_velocity_threshold" 7 "min_interval" 8 "position_kp" 9 "position_ki" 10 "max_position_threshold" 11 "telemetry_packet_1_speed" 12 "telemetry_packet_2_speed" 13 "telemetry_packet_3_speed" 14 "telemetry_packet_4_speed" ;
VAL_ 89 configuration 0 "has_resolver" 1 "current_kp" 2 "current_ki" 3 "max_current_threshold" 4 "velocity_kp" 5 "velocity_ki" 6 "max_velocity_threshold" 7 "min_interval" 8 "position_kp" 9 "position_ki" 10 "max_position_threshold" 11 "telemetry_packet_1_speed" 12 "telemetry_packet_2_speed" 13 "telemetry_packet_3_speed" 14 "telemetry_packet_4_speed" ;
VAL_ 90 value 0 "false" 1 "true" ;
VAL_ 90 configuration 0 "has_resolver" 1 "current_kp" 2 "current_ki" 3 "max_current_threshold" 4 "velocity_kp" 5 "velocity_ki" 6 "max_velocity_threshold" 7 "min_interval" 8 "position_kp" 9 "position_ki" 10 "max_position_threshold" 11 "telemetry_packet_1_speed" 12 "telemetry_packet_2_speed" 13 "telemetry_packet_3_speed" 14 "telemetry_packet_4_speed" ;
VAL_ 1104 gate_driver_condition 255 "log_sequence_complete" ;
VAL_ 1104 info_message 0 "gate_driver_config_success" 1 "ma302_config_success" 2 "gate_driver_fault_recovered" 3 "rotor_home_success" 4 "resolver_zero_success" ;
VAL_ 1104 warning_message 0 "missing_steps" 1 "duty_cycle_threshold" 2 "current_threshold" 3 "velocity_threshold" 4 "position_out_of_range" ;
VAL_ 1104 error_message 0 "no_steps" 1 "magnetic_encoder_error" 2 "resolver_error" 3 "resolver_failed_checksum" 4 "unexpected_position_command" 5 "gate_driver_fault" 6 "gate_driver_spi_failed" 7 "ma302_spi_failed" 8 "rotor_home_failed" 9 "resolver_zero_failure" 10 "stall_triggered" 11 "over_speed" 12 "over_acceleration" 13 "encoder_fault" ;
VAL_ 1104 log_message 0 "error" 1 "warning" 2 "info" 3 "gate_driver_condition" ;
VAL_ 1113 value 0 "false" 1 "true" ;
VAL_ 1113 configuration 0 "has_resolver" 1 "current_kp" 2 "current_ki" 3 "max_current_threshold" 4 "velocity_kp" 5 "velocity_ki" 6 "max_velocity_threshold" 7 "min_interval" 8 "position_kp" 9 "position_ki" 10 "max_position_threshold" 11 "telemetry_packet_1_speed" 12 "telemetry_packet_2_speed" 13 "telemetry_packet_3_speed" 14 "telemetry_packet_4_speed" ;
VAL_ 105 configuration 0 "has_resolver" 1 "current_kp" 2 "current_ki" 3 "max_current_threshold" 4 "velocity_kp" 5 "velocity_ki" 6 "max_velocity_threshold" 7 "min_interval" 8 "position_kp" 9 "position_ki" 10 "max_position_threshold" 11 "telemetry_packet_1_speed" 12 "telemetry_packet_2_speed" 13 "telemetry_packet_3_speed" 14 "telemetry_packet_4_speed" ;
VAL_ 106 value 0 "false" 1 "true" ;
VAL_ 106 configuration 0 "has_resolver" 1 "current_kp" 2 "current_ki" 3 "max_current_threshold" 4 "velocity_kp" 5 "velocity_ki" 6 "max_velocity_threshold" 7 "min_interval" 8 "position_kp" 9 "position_ki" 10 "max_position_threshold" 11 "telemetry_packet_1_speed" 12 "telemetry_packet_2_speed" 13 "telemetry_packet_3_speed" 14 "telemetry_packet_4_speed" ;
VAL_ 1120 gate_driver_condition 255 "log_sequence_complete" ;
VAL_ 1120 info_message 0 "gate_driver_config_success" 1 "ma302_config_success" 2 "gate_driver_fault_recovered" 3 "rotor_home_success" 4 "resolver_zero_success" ;
VAL_ 1120 warning_message 0 "missing_steps" 1 "duty_cycle_threshold" 2 "current_threshold" 3 "velocity_threshold" 4 "position_out_of_range" ;
VAL_ 1120 error_message 0 "no_steps" 1 "magnetic_encoder_error" 2 "resolver_error" 3 "resolver_failed_checksum" 4 "unexpected_position_command" 5 "gate_driver_fault" 6 "gate_driver_spi_failed" 7 "ma302_spi_failed" 8 "rotor_home_failed" 9 "resolver_zero_failure" 10 "stall_triggered" 11 "over_speed" 12 "over_acceleration" 13 "encoder_fault" ;
VAL_ 1120 log_message 0 "error" 1 "warning" 2 "info" 3 "gate_driver_condition" ;
VAL_ 1129 value 0 "false" 1 "true" ;
VAL_ 1129 configuration 0 "has_resolver" 1 "current_kp" 2 "current_ki" 3 "max_current_threshold" 4 "velocity_kp" 5 "velocity_ki" 6 "max_velocity_threshold" 7 "min_interval" 8 "position_kp" 9 "position_ki" 10 "max_position_threshold" 11 "telemetry_packet_1_speed" 12 "telemetry_packet_2_speed" 13 "telemetry_packet_3_speed" 14 "telemetry_packet_4_speed" ;
VAL_ 121 configuration 0 "has_resolver" 1 "current_kp" 2 "current_ki" 3 "max_current_threshold" 4 "velocity_kp" 5 "velocity_ki" 6 "max_velocity_threshold" 7 "min_interval" 8 "position_kp" 9 "position_ki" 10 "max_position_threshold" 11 "telemetry_packet_1_speed" 12 "telemetry_packet_2_speed" 13 "telemetry_packet_3_speed" 14 "telemetry_packet_4_speed" ;
VAL_ 122 value 0 "false" 1 "true" ;
VAL_ 122 configuration 0 "has_resolver" 1 "current_kp" 2 "current_ki" 3 "max_current_threshold" 4 "velocity_kp" 5 "velocity_ki" 6 "max_velocity_threshold" 7 "min_interval" 8 "position_kp" 9 "position_ki" 10 "max_position_threshold" 11 "telemetry_packet_1_speed" 12 "telemetry_packet_2_speed" 13 "telemetry_packet_3_speed" 14 "telemetry_packet_4_speed" ;
VAL_ 1136 gate_driver_condition 255 "log_sequence_complete" ;
VAL_ 1136 info_message 0 "gate_driver_config_success" 1 "ma302_config_success" 2 "gate_driver_fault_recovered" 3 "rotor_home_success" 4 "resolver_zero_success" ;
VAL_ 1136 warning_message 0 "missing_steps" 1 "duty_cycle_threshold" 2 "current_threshold" 3 "velocity_threshold" 4 "position_out_of_range" ;
VAL_ 1136 error_message 0 "no_steps" 1 "magnetic_encoder_error" 2 "resolver_error" 3 "resolver_failed_checksum" 4 "unexpected_position_command" 5 "gate_driver_fault" 6 "gate_driver_spi_failed" 7 "ma302_spi_failed" 8 "rotor_home_failed" 9 "resolver_zero_failure" 10 "stall_triggered" 11 "over_speed" 12 "over_acceleration" 13 "encoder_fault" ;
VAL_ 1136 log_message 0 "error" 1 "warning" 2 "info" 3 "gate_driver_condition" ;
VAL_ 1145 value 0 "false" 1 "true" ;
VAL_ 1145 configuration 0 "has_resolver" 1 "current_kp" 2 "current_ki" 3 "max_current_threshold" 4 "velocity_kp" 5 "velocity_ki" 6 "max_velocity_threshold" 7 "min_interval" 8 "position_kp" 9 "position_ki" 10 "max_position_threshold" 11 "telemetry_packet_1_speed" 12 "telemetry_packet_2_speed" 13 "telemetry_packet_3_speed" 14 "telemetry_packet_4_speed" ;
VAL_ 137 configuration 0 "has_resolver" 1 "current_kp" 2 "current_ki" 3 "max_current_threshold" 4 "velocity_kp" 5 "velocity_ki" 6 "max_velocity_threshold" 7 "min_interval" 8 "position_kp" 9 "position_ki" 10 "max_position_threshold" 11 "telemetry_packet_1_speed" 12 "telemetry_packet_2_speed" 13 "telemetry_packet_3_speed" 14 "telemetry_packet_4_speed" ;
VAL_ 138 value 0 "false" 1 "true" ;
VAL_ 138 configuration 0 "has_resolver" 1 "current_kp" 2 "current_ki" 3 "max_current_threshold" 4 "velocity_kp" 5 "velocity_ki" 6 "max_velocity_threshold" 7 "min_interval" 8 "position_kp" 9 "position_ki" 10 "max_position_threshold" 11 "telemetry_packet_1_speed" 12 "telemetry_packet_2_speed" 13 "telemetry_packet_3_speed" 14 "telemetry_packet_4_speed" ;
VAL_ 1152 gate_driver_condition 255 "log_sequence_complete" ;
VAL_ 1152 info_message 0 "gate_driver_config_success" 1 "ma302_config_success" 2 "gate_driver_fault_recovered" 3 "rotor_home_success" 4 "resolver_zero_success" ;
VAL_ 1152 warning_message 0 "missing_steps" 1 "duty_cycle_threshold" 2 "current_threshold" 3 "velocity_threshold" 4 "position_out_of_range" ;
VAL_ 1152 error_message 0 "no_steps" 1 "magnetic_encoder_error" 2 "resolver_error" 3 "resolver_failed_checksum" 4 "unexpected_position_command" 5 "gate_driver_fault" 6 "gate_driver_spi_failed" 7 "ma302_spi_failed" 8 "rotor_home_failed" 9 "resolver_zero_failure" 10 "stall_triggered" 11 "over_speed" 12 "over_acceleration" 13 "encoder_fault" ;
VAL_ 1152 log_message 0 "error" 1 "warning" 2 "info" 3 "gate_driver_condition" ;
VAL_ 1161 value 0 "false" 1 "true" ;
VAL_ 1161 configuration 0 "has_resolver" 1 "current_kp" 2 "current_ki" 3 "max_current_threshold" 4 "velocity_kp" 5 "velocity_ki" 6 "max_velocity_threshold" 7 "min_interval" 8 "position_kp" 9 "position_ki" 10 "max_position_threshold" 11 "telemetry_packet_1_speed" 12 "telemetry_packet_2_speed" 13 "telemetry_packet_3_speed" 14 "telemetry_packet_4_speed" ;
